VERSION "0.6.1"

NS_ :

BS_:

BU_: TestPC PVOptimizer HomeController Battery Inverter IPC
VAL_TABLE_ INV_State_Enum 3 "Fault" 2 "Grid_Forming" 1 "AC_Relays_Open" 0 "Unknown" ;
VAL_TABLE_ BB_State_Enum 4 "Fault" 3 "Block_Down" 2 "Active" 1 "Low_Voltage" 0 "Unknown" ;

BO_ 2150630656 BB_Control: 1 INV
 SG_ BB_StateReq : 0|8@1+ (1,0) [0|255] "" Vector__XXX

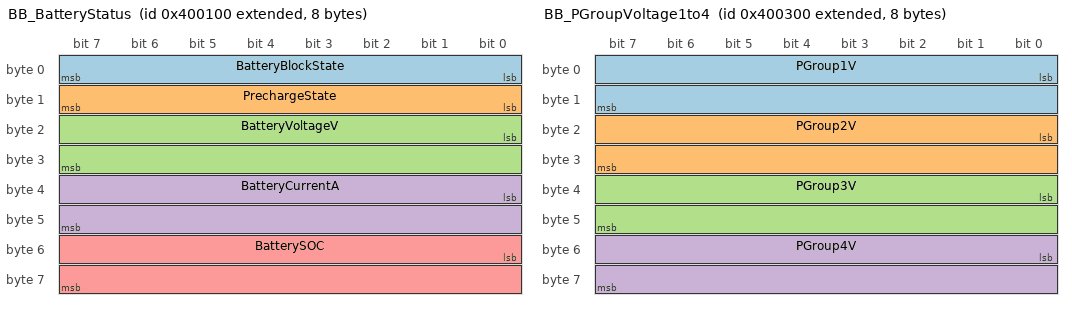
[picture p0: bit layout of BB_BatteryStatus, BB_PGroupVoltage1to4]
BO_ 2151678208 BB_BatteryStatus: 8 BB
 SG_ BatteryBlockState : 0|8@1+ (1,0) [0|255] "" Vector__XXX
 SG_ PrechargeState : 8|8@1+ (1,0) [0|255] "" Vector__XXX
 SG_ BatteryVoltageV : 16|16@1+ (0.001,0) [0|65.535] "V" Vector__XXX
 SG_ BatteryCurrentA : 32|16@1- (0.005,0) [-163.84|163.835] "A" Vector__XXX
 SG_ BatterySOC : 48|16@1+ (0.1,0) [0|100] "%" Vector__XXX

BO_ 2151678464 BB_DCDCStatus: 4 BB
 SG_ DCBusVoltageV : 0|16@1+ (0.01,0) [0|655.35] "V" Vector__XXX
 SG_ DCBusCurrentA : 16|16@1- (0.005,0) [-163.84|163.835] "A" Vector__XXX

BO_ 2151678720 BB_PGroupVoltage1to4: 8 BB
 SG_ PGroup1V : 0|16@1+ (0.0001,0) [0|6.5535000000000005] "V" Vector__XXX
 SG_ PGroup2V : 16|16@1+ (0.0001,0) [0|6.5535000000000005] "V" Vector__XXX
 SG_ PGroup3V : 32|16@1+ (0.0001,0) [0|6.5535000000000005] "V" Vector__XXX
 SG_ PGroup4V : 48|16@1+ (0.0001,0) [0|6.5535000000000005] "V" Vector__XXX

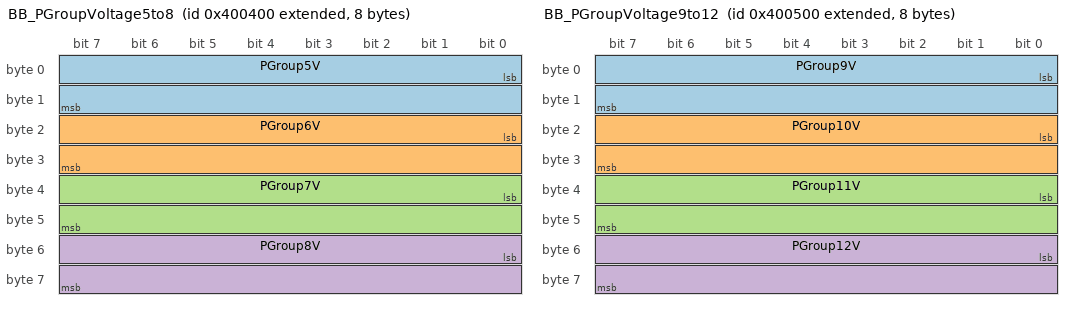
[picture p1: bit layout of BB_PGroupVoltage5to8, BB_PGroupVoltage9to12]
BO_ 2151678976 BB_PGroupVoltage5to8: 8 BB
 SG_ PGroup5V : 0|16@1+ (0.0001,0) [0|6.5535000000000005] "V" Vector__XXX
 SG_ PGroup6V : 16|16@1+ (0.0001,0) [0|6.5535000000000005] "V" Vector__XXX
 SG_ PGroup7V : 32|16@1+ (0.0001,0) [0|6.5535000000000005] "V" Vector__XXX
 SG_ PGroup8V : 48|16@1+ (0.0001,0) [0|6.5535000000000005] "V" Vector__XXX

BO_ 2151679232 BB_PGroupVoltage9to12: 8 BB
 SG_ PGroup9V : 0|16@1+ (0.0001,0) [0|6.5535000000000005] "V" Vector__XXX
 SG_ PGroup10V : 16|16@1+ (0.0001,0) [0|6.5535000000000005] "V" Vector__XXX
 SG_ PGroup11V : 32|16@1+ (0.0001,0) [0|6.5535000000000005] "V" Vector__XXX
 SG_ PGroup12V : 48|16@1+ (0.0001,0) [0|6.5535000000000005] "V" Vector__XXX

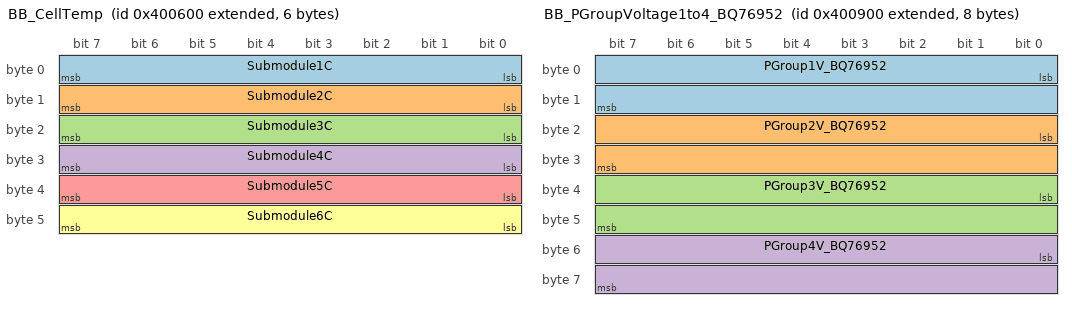
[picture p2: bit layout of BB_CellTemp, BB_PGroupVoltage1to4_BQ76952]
BO_ 2151679488 BB_CellTemp: 6 BB
 SG_ Submodule1C : 0|8@1+ (0.5,-40) [-40|87.5] "Celsius" Vector__XXX
 SG_ Submodule2C : 8|8@1+ (0.5,-40) [-40|87.5] "Celsius" Vector__XXX
 SG_ Submodule3C : 16|8@1+ (0.5,-40) [-40|87.5] "Celsius" Vector__XXX
 SG_ Submodule4C : 24|8@1+ (0.5,-40) [-40|87.5] "Celsius" Vector__XXX
 SG_ Submodule5C : 32|8@1+ (0.5,-40) [-40|87.5] "Celsius" Vector__XXX
 SG_ Submodule6C : 40|8@1+ (0.5,-40) [-40|87.5] "Celsius" Vector__XXX

BO_ 2151679744 BB_DCDCTemperatures: 3 BB
 SG_ BBHeatsinkC : 0|8@1+ (1,-60) [-60|195] "Celsius" Vector__XXX
 SG_ FanDutyCycle : 8|16@1+ (0.1,0) [0|100] "%" Vector__XXX

BO_ 2151680000 BB_CommandResetCMD: 1 BB
 SG_ BB_ResetReq : 0|8@1+ (1,0) [0|255] "" Vector__XXX

BO_ 2151680256 BB_PGroupVoltage1to4_BQ76952: 8 BB
 SG_ PGroup1V_BQ76952 : 0|16@1+ (0.0001,0) [0|6.5535000000000005] "V" Vector__XXX
 SG_ PGroup2V_BQ76952 : 16|16@1+ (0.0001,0) [0|6.5535000000000005] "V" Vector__XXX
 SG_ PGroup3V_BQ76952 : 32|16@1+ (0.0001,0) [0|6.5535000000000005] "V" Vector__XXX
 SG_ PGroup4V_BQ76952 : 48|16@1+ (0.0001,0) [0|6.5535000000000005] "V" Vector__XXX

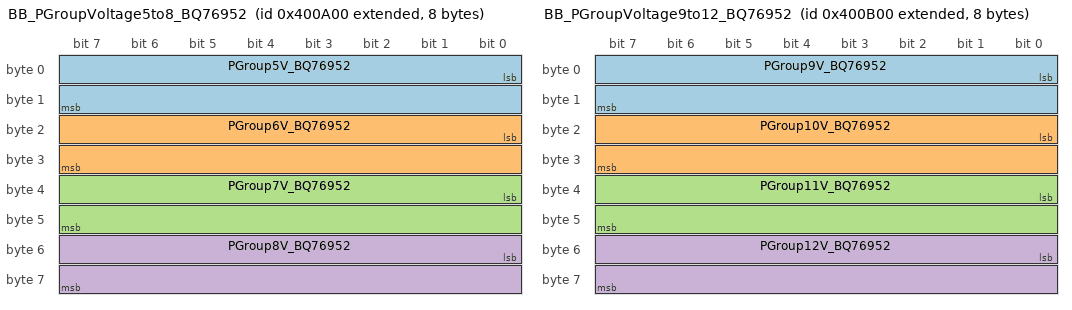
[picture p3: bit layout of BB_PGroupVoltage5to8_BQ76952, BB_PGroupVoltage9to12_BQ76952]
BO_ 2151680512 BB_PGroupVoltage5to8_BQ76952: 8 BB
 SG_ PGroup5V_BQ76952 : 0|16@1+ (0.0001,0) [0|6.5535000000000005] "V" Vector__XXX
 SG_ PGroup6V_BQ76952 : 16|16@1+ (0.0001,0) [0|6.5535000000000005] "V" Vector__XXX
 SG_ PGroup7V_BQ76952 : 32|16@1+ (0.0001,0) [0|6.5535000000000005] "V" Vector__XXX
 SG_ PGroup8V_BQ76952 : 48|16@1+ (0.0001,0) [0|6.5535000000000005] "V" Vector__XXX

BO_ 2151680768 BB_PGroupVoltage9to12_BQ76952: 8 BB
 SG_ PGroup9V_BQ76952 : 0|16@1+ (0.0001,0) [0|6.5535000000000005] "V" Vector__XXX
 SG_ PGroup10V_BQ76952 : 16|16@1+ (0.0001,0) [0|6.5535000000000005] "V" Vector__XXX
 SG_ PGroup11V_BQ76952 : 32|16@1+ (0.0001,0) [0|6.5535000000000005] "V" Vector__XXX
 SG_ PGroup12V_BQ76952 : 48|16@1+ (0.0001,0) [0|6.5535000000000005] "V" Vector__XXX

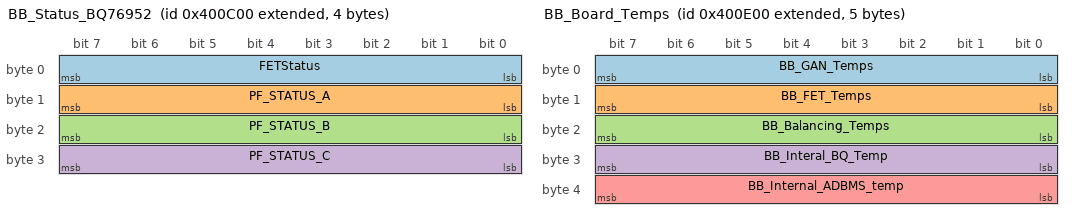
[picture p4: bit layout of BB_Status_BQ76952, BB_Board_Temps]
BO_ 2151681024 BB_Status_BQ76952: 4 BB
 SG_ FETStatus : 0|8@1+ (1,0) [0|255] "" Vector__XXX
 SG_ PF_STATUS_A : 8|8@1+ (1,0) [0|255] "" Vector__XXX
 SG_ PF_STATUS_B : 16|8@1+ (1,0) [0|255] "" Vector__XXX
 SG_ PF_STATUS_C : 24|8@1+ (1,0) [0|255] "" Vector__XXX

BO_ 2151681280 BB_Interrupt_Status: 5 BB
 SG_ BB_10Hz_Runtime : 0|32@1+ (1,0) [0|4294967295] "" Vector__XXX
 SG_ BB_Percent_Usage_10hz : 32|8@1+ (1,0) [0|255] "" Vector__XXX

BO_ 2151681536 BB_Board_Temps: 5 BB
 SG_ BB_GAN_Temps : 0|8@1+ (0.5,-40) [-40|87.5] "Celsius" Vector__XXX
 SG_ BB_FET_Temps : 8|8@1+ (0.5,-40) [-40|87.5] "Celsius" Vector__XXX
 SG_ BB_Balancing_Temps : 16|8@1+ (0.5,-40) [-40|87.5] "Celsius" Vector__XXX
 SG_ BB_Interal_BQ_Temp : 24|8@1+ (0.5,-40) [-40|87.5] "Celsius" Vector__XXX
 SG_ BB_Internal_ADBMS_temp : 32|8@1+ (0.5,-40) [-40|87.5] "Celsius" Vector__XXX

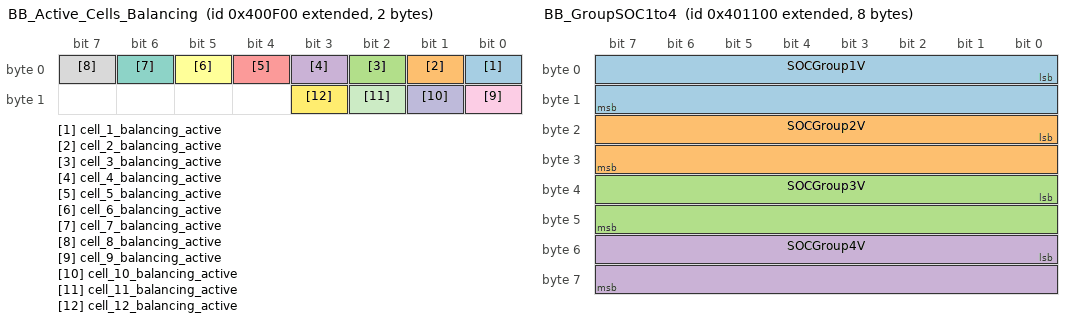
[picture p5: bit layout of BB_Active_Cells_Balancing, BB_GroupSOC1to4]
BO_ 2151681792 BB_Active_Cells_Balancing: 2 BB
 SG_ cell_1_balancing_active : 0|1@1+ (1,0) [0|1] "" Vector__XXX
 SG_ cell_2_balancing_active : 1|1@1+ (1,0) [0|1] "" Vector__XXX
 SG_ cell_3_balancing_active : 2|1@1+ (1,0) [0|1] "" Vector__XXX
 SG_ cell_4_balancing_active : 3|1@1+ (1,0) [0|1] "" Vector__XXX
 SG_ cell_5_balancing_active : 4|1@1+ (1,0) [0|1] "" Vector__XXX
 SG_ cell_6_balancing_active : 5|1@1+ (1,0) [0|1] "" Vector__XXX
 SG_ cell_7_balancing_active : 6|1@1+ (1,0) [0|1] "" Vector__XXX
 SG_ cell_8_balancing_active : 7|1@1+ (1,0) [0|1] "" Vector__XXX
 SG_ cell_9_balancing_active : 8|1@1+ (1,0) [0|1] "" Vector__XXX
 SG_ cell_10_balancing_active : 9|1@1+ (1,0) [0|1] "" Vector__XXX
 SG_ cell_11_balancing_active : 10|1@1+ (1,0) [0|1] "" Vector__XXX
 SG_ cell_12_balancing_active : 11|1@1+ (1,0) [0|1] "" Vector__XXX

BO_ 2151682304 BB_GroupSOC1to4: 8 BB
 SG_ SOCGroup1V : 0|16@1+ (0.1,0) [0|100] "%" Vector__XXX
 SG_ SOCGroup2V : 16|16@1+ (0.1,0) [0|100] "%" Vector__XXX
 SG_ SOCGroup3V : 32|16@1+ (0.1,0) [0|100] "%" Vector__XXX
 SG_ SOCGroup4V : 48|16@1+ (0.1,0) [0|100] "%" Vector__XXX

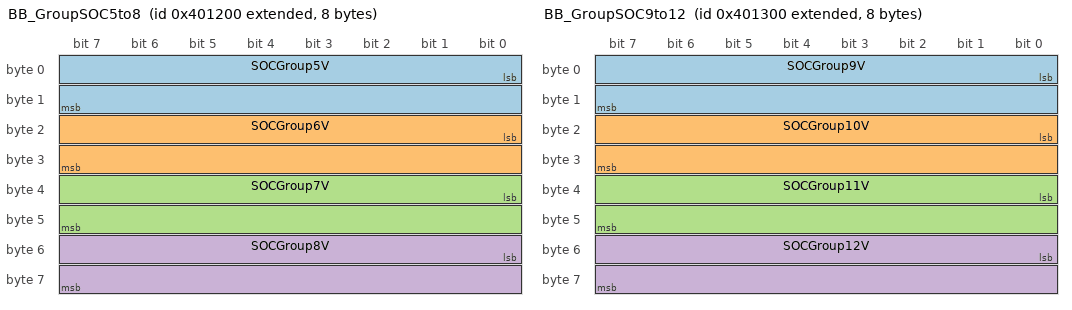
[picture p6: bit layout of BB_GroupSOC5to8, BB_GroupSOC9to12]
BO_ 2151682560 BB_GroupSOC5to8: 8 BB
 SG_ SOCGroup5V : 0|16@1+ (0.1,0) [0|100] "%" Vector__XXX
 SG_ SOCGroup6V : 16|16@1+ (0.1,0) [0|100] "%" Vector__XXX
 SG_ SOCGroup7V : 32|16@1+ (0.1,0) [0|100] "%" Vector__XXX
 SG_ SOCGroup8V : 48|16@1+ (0.1,0) [0|100] "%" Vector__XXX

BO_ 2151682816 BB_GroupSOC9to12: 8 BB
 SG_ SOCGroup9V : 0|16@1+ (0.1,0) [0|100] "%" Vector__XXX
 SG_ SOCGroup10V : 16|16@1+ (0.1,0) [0|100] "%" Vector__XXX
 SG_ SOCGroup11V : 32|16@1+ (0.1,0) [0|100] "%" Vector__XXX
 SG_ SOCGroup12V : 48|16@1+ (0.1,0) [0|100] "%" Vector__XXX

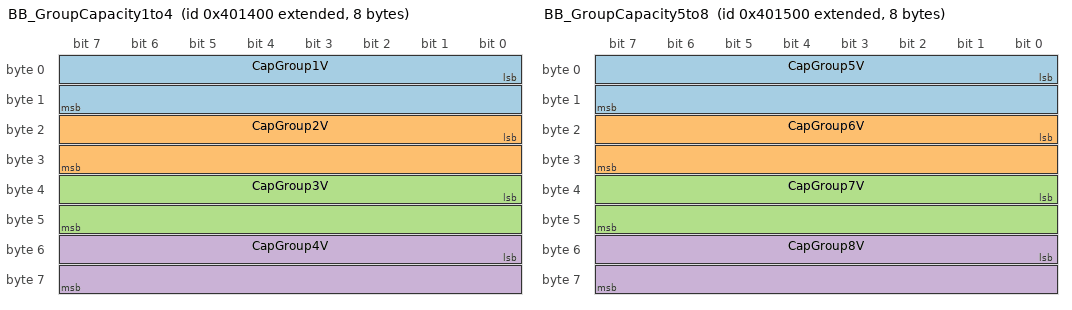
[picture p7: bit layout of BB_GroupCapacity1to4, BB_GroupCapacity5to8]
BO_ 2151683072 BB_GroupCapacity1to4: 8 BB
 SG_ CapGroup1V : 0|16@1+ (0.1,0) [0|100] "%" Vector__XXX
 SG_ CapGroup2V : 16|16@1+ (0.1,0) [0|100] "%" Vector__XXX
 SG_ CapGroup3V : 32|16@1+ (0.1,0) [0|100] "%" Vector__XXX
 SG_ CapGroup4V : 48|16@1+ (0.1,0) [0|100] "%" Vector__XXX

BO_ 2151683328 BB_GroupCapacity5to8: 8 BB
 SG_ CapGroup5V : 0|16@1+ (0.1,0) [0|100] "%" Vector__XXX
 SG_ CapGroup6V : 16|16@1+ (0.1,0) [0|100] "%" Vector__XXX
 SG_ CapGroup7V : 32|16@1+ (0.1,0) [0|100] "%" Vector__XXX
 SG_ CapGroup8V : 48|16@1+ (0.1,0) [0|100] "%" Vector__XXX

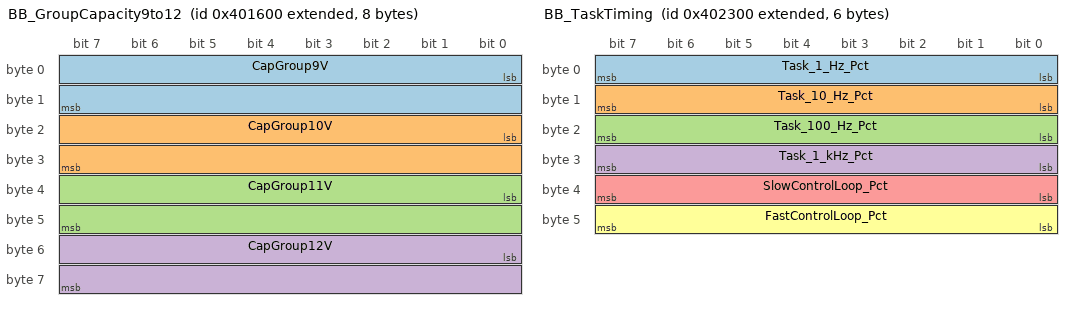
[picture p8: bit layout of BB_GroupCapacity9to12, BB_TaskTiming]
BO_ 2151683584 BB_GroupCapacity9to12: 8 BB
 SG_ CapGroup9V : 0|16@1+ (0.1,0) [0|100] "%" Vector__XXX
 SG_ CapGroup10V : 16|16@1+ (0.1,0) [0|100] "%" Vector__XXX
 SG_ CapGroup11V : 32|16@1+ (0.1,0) [0|100] "%" Vector__XXX
 SG_ CapGroup12V : 48|16@1+ (0.1,0) [0|100] "%" Vector__XXX

BO_ 2151683840 BB_Status_PF_Safety: 7 BB
 SG_ Reserved_0A : 0|1@1+ (1,0) [0|1] "" Vector__XXX
 SG_ Reserved_1A : 1|1@1+ (1,0) [0|1] "" Vector__XXX
 SG_ SafetyStatusA_CellUV_fault : 2|1@1+ (1,0) [0|1] "" Vector__XXX
 SG_ SafetyStatusA_CellOV_fault : 3|1@1+ (1,0) [0|1] "" Vector__XXX
 SG_ SatefyStatusA_OCCharge_fault : 4|1@1+ (1,0) [0|1] "" Vector__XXX
 SG_ SatefyStatusA_OCDischarge1_fault : 5|1@1+ (1,0) [0|1] "" Vector__XXX
 SG_ SatefyStatusA_OCDischarge2_fault : 6|1@1+ (1,0) [0|1] "" Vector__XXX
 SG_ SatefyStatusA_OCDischargeProt_fa : 7|1@1+ (1,0) [0|1] "" Vector__XXX
 SG_ SafetyStatusB_UTempCharge_fault : 8|1@1+ (1,0) [0|1] "" Vector__XXX
 SG_ SafetyStatusB_UTempDischarge_fau : 9|1@1+ (1,0) [0|1] "" Vector__XXX
 SG_ SafetyStatusB_IntUTemp_fault : 10|1@1+ (1,0) [0|1] "" Vector__XXX
 SG_ Reserved_11A : 11|1@1+ (1,0) [0|1] "" Vector__XXX
 SG_ SafetyStatusB_OTempCharge_fault : 12|1@1+ (1,0) [0|1] "" Vector__XXX
 SG_ SafetyStatusB_OTempDischarge_fau : 13|1@1+ (1,0) [0|1] "" Vector__XXX
 SG_ SafetyStatusB_IntOTemp_fault : 14|1@1+ (1,0) [0|1] "" Vector__XXX
 SG_ SatefyStatusB_FETOTemp_fault : 15|1@1+ (1,0) [0|1] "" Vector__XXX
 SG_ Reserved_16A : 16|1@1+ (1,0) [0|1] "" Vector__XXX
 SG_ SafetyStatusC_HostWDT_fault : 17|1@1+ (1,0) [0|1] "" Vector__XXX
 SG_ SafetyStatusC_PchgTimeout_fault : 18|1@1+ (1,0) [0|1] "" Vector__XXX
 SG_ Reserved_19A : 19|1@1+ (1,0) [0|1] "" Vector__XXX
 SG_ SafetyStatusC_COVLatch_fault : 20|1@1+ (1,0) [0|1] "" Vector__XXX
 SG_ SafetyStatusC_OCDischgLatch_faul : 21|1@1+ (1,0) [0|1] "" Vector__XXX
 SG_ SafetyStatusC_SCDischgLatch_faul : 22|1@1+ (1,0) [0|1] "" Vector__XXX
 SG_ SafetyStatusC_OCDischarge3_fault : 23|1@1+ (1,0) [0|1] "" Vector__XXX
 SG_ PFStatusA_CellUV_fault : 24|1@1+ (1,0) [0|1] "" Vector__XXX
 SG_ PFStatusA_CellOV_fault : 25|1@1+ (1,0) [0|1] "" Vector__XXX
 SG_ PFStatusA_OCCharge_fault : 26|1@1+ (1,0) [0|1] "" Vector__XXX
 SG_ PFStatusA_OCDischarge_fault : 27|1@1+ (1,0) [0|1] "" Vector__XXX
 SG_ PFStatusA_OT_fault : 28|1@1+ (1,0) [0|1] "" Vector__XXX
 SG_ Reserved_29A : 29|1@1+ (1,0) [0|1] "" Vector__XXX
 SG_ PFStatusA_CellOT_fault : 30|1@1+ (1,0) [0|1] "" Vector__XXX
 SG_ PFStatusA_CopperDepo_fault : 31|1@1+ (1,0) [0|1] "" Vector__XXX
 SG_ PFStatusB_ChgFet_fault : 32|1@1+ (1,0) [0|1] "" Vector__XXX
 SG_ PFStatusB_DChgFet_fault : 33|1@1+ (1,0) [0|1] "" Vector__XXX
 SG_ PFStatusB_2ndLvlProtFault : 34|1@1+ (1,0) [0|1] "" Vector__XXX
 SG_ PFStatusB_VImbalanceRest_fault : 35|1@1+ (1,0) [0|1] "" Vector__XXX
 SG_ PFStatusB_VImbalanceActive_fault : 36|1@1+ (1,0) [0|1] "" Vector__XXX
 SG_ Reserved_37A : 37|1@1+ (1,0) [0|1] "" Vector__XXX
 SG_ Reserved_38A : 38|1@1+ (1,0) [0|1] "" Vector__XXX
 SG_ PFStatusB_SCDischargeLatch_fault : 39|1@1+ (1,0) [0|1] "" Vector__XXX
 SG_ PFStatusC_OTPMem_fault : 40|1@1+ (1,0) [0|1] "" Vector__XXX
 SG_ PFStatusC_DataROM_fault : 41|1@1+ (1,0) [0|1] "" Vector__XXX
 SG_ PFStatusC_InstrROM_fault : 42|1@1+ (1,0) [0|1] "" Vector__XXX
 SG_ PFStatusC_IntLFO_fault : 43|1@1+ (1,0) [0|1] "" Vector__XXX
 SG_ PFStatusC_IntVRef_fault : 44|1@1+ (1,0) [0|1] "" Vector__XXX
 SG_ PFStatusC_IntVSS_fault : 45|1@1+ (1,0) [0|1] "" Vector__XXX
 SG_ PFStatusC_HrdwreMux_fault : 46|1@1+ (1,0) [0|1] "" Vector__XXX
 SG_ PFStatusC_Commanded_fault : 47|1@1+ (1,0) [0|1] "" Vector__XXX
 SG_ PFStatusD_StackVsSum_fault : 48|1@1+ (1,0) [0|1] "" Vector__XXX
 SG_ Reserved_49A : 49|1@1+ (1,0) [0|1] "" Vector__XXX
 SG_ Reserved_40A : 50|1@1+ (1,0) [0|1] "" Vector__XXX
 SG_ Reserved_51A : 51|1@1+ (1,0) [0|1] "" Vector__XXX
 SG_ Reserved_52A : 52|1@1+ (1,0) [0|1] "" Vector__XXX
 SG_ Reserved_53A : 53|1@1+ (1,0) [0|1] "" Vector__XXX
 SG_ Reserved_54A : 54|1@1+ (1,0) [0|1] "" Vector__XXX
 SG_ Reserved_55A : 55|1@1+ (1,0) [0|1] "" Vector__XXX

BO_ 2151684096 BB_Alert_PF_Safety: 7 BB
 SG_ Reserved_0B : 0|1@1+ (1,0) [0|1] "" Vector__XXX
 SG_ Reserved_1B : 1|1@1+ (1,0) [0|1] "" Vector__XXX
 SG_ SafetyAlertA_CellUV_alert : 2|1@1+ (1,0) [0|1] "" Vector__XXX
 SG_ SafetyAlertA_CellOV_alert : 3|1@1+ (1,0) [0|1] "" Vector__XXX
 SG_ SatefyAlertA_OCCharge_alert : 4|1@1+ (1,0) [0|1] "" Vector__XXX
 SG_ SatefyAlertA_OCDischarge1_alert : 5|1@1+ (1,0) [0|1] "" Vector__XXX
 SG_ SatefyAlertA_OCDischarge2_alert : 6|1@1+ (1,0) [0|1] "" Vector__XXX
 SG_ SatefyAlertA_OCDischargeProt_ale : 7|1@1+ (1,0) [0|1] "" Vector__XXX
 SG_ SafetyAlertB_UTempCharge_alert : 8|1@1+ (1,0) [0|1] "" Vector__XXX
 SG_ SafetyAlertB_UTempDischarge_aler : 9|1@1+ (1,0) [0|1] "" Vector__XXX
 SG_ SafetyAlertB_IntUTemp_alert : 10|1@1+ (1,0) [0|1] "" Vector__XXX
 SG_ Reserved_11B : 11|1@1+ (1,0) [0|1] "" Vector__XXX
 SG_ SafetyAlertB_OTempCharge_alert : 12|1@1+ (1,0) [0|1] "" Vector__XXX
 SG_ SafetyAlertB_OTempDischarge_aler : 13|1@1+ (1,0) [0|1] "" Vector__XXX
 SG_ SafetyAlertB_IntOTemp_alert : 14|1@1+ (1,0) [0|1] "" Vector__XXX
 SG_ SatefyAlertB_FETOTemp_alert : 15|1@1+ (1,0) [0|1] "" Vector__XXX
 SG_ Reserved_16B : 16|1@1+ (1,0) [0|1] "" Vector__XXX
 SG_ Reserved_17B : 17|1@1+ (1,0) [0|1] "" Vector__XXX
 SG_ Reserved_18B : 18|1@1+ (1,0) [0|1] "" Vector__XXX
 SG_ SafetyAlertC_PchgTimeout_alert : 19|1@1+ (1,0) [0|1] "" Vector__XXX
 SG_ SafetyAlertC_COVLatch_alert : 20|1@1+ (1,0) [0|1] "" Vector__XXX
 SG_ SafetyAlertC_OCDischgLatch_alert : 21|1@1+ (1,0) [0|1] "" Vector__XXX
 SG_ SafetyAlertC_SCDischgLatch_alert : 22|1@1+ (1,0) [0|1] "" Vector__XXX
 SG_ SafetyAlertC_OCDischarge3_alert : 23|1@1+ (1,0) [0|1] "" Vector__XXX
 SG_ PFAlertA_CellUV_alert : 24|1@1+ (1,0) [0|1] "" Vector__XXX
 SG_ PFAlertA_CellOV_alert : 25|1@1+ (1,0) [0|1] "" Vector__XXX
 SG_ PFAlertA_OCCharge_alert : 26|1@1+ (1,0) [0|1] "" Vector__XXX
 SG_ PFAlertA_OCDischarge_alert : 27|1@1+ (1,0) [0|1] "" Vector__XXX
 SG_ PFAlertA_OT_alert : 28|1@1+ (1,0) [0|1] "" Vector__XXX
 SG_ Reserved_29B : 29|1@1+ (1,0) [0|1] "" Vector__XXX
 SG_ PFAlertA_CellOT_alert : 30|1@1+ (1,0) [0|1] "" Vector__XXX
 SG_ PFAlertA_CopperDepo_alert : 31|1@1+ (1,0) [0|1] "" Vector__XXX
 SG_ PFAlertB_ChgFet_alert : 32|1@1+ (1,0) [0|1] "" Vector__XXX
 SG_ PFAlertB_DChgFet_alert : 33|1@1+ (1,0) [0|1] "" Vector__XXX
 SG_ PFAlertB_2ndLvlProt_alert : 34|1@1+ (1,0) [0|1] "" Vector__XXX
 SG_ PFAlertB_VImbalanceRest_alert : 35|1@1+ (1,0) [0|1] "" Vector__XXX
 SG_ PFAlertB_VImbalanceActive_alert : 36|1@1+ (1,0) [0|1] "" Vector__XXX
 SG_ Reserved_37B : 37|1@1+ (1,0) [0|1] "" Vector__XXX
 SG_ Reserved_38B : 38|1@1+ (1,0) [0|1] "" Vector__XXX
 SG_ PFAlertB_SCDischargeLatch_alert : 39|1@1+ (1,0) [0|1] "" Vector__XXX
 SG_ Reserved_40B : 40|1@1+ (1,0) [0|1] "" Vector__XXX
 SG_ Reserved_41B : 41|1@1+ (1,0) [0|1] "" Vector__XXX
 SG_ Reserved_42B : 42|1@1+ (1,0) [0|1] "" Vector__XXX
 SG_ PFAlertC_IntLFO_alert : 43|1@1+ (1,0) [0|1] "" Vector__XXX
 SG_ PFAlertC_IntVRef_alert : 44|1@1+ (1,0) [0|1] "" Vector__XXX
 SG_ PFAlertC_IntVSS_alert : 45|1@1+ (1,0) [0|1] "" Vector__XXX
 SG_ PFAlertC_HrdwreMux_alert : 46|1@1+ (1,0) [0|1] "" Vector__XXX
 SG_ Reserved_47B : 47|1@1+ (1,0) [0|1] "" Vector__XXX
 SG_ PFAlertD_StackVsSum_alert : 48|1@1+ (1,0) [0|1] "" Vector__XXX
 SG_ Reserved_49B : 49|1@1+ (1,0) [0|1] "" Vector__XXX
 SG_ Reserved_50B : 50|1@1+ (1,0) [0|1] "" Vector__XXX
 SG_ Reserved_51B : 51|1@1+ (1,0) [0|1] "" Vector__XXX
 SG_ Reserved_52B : 52|1@1+ (1,0) [0|1] "" Vector__XXX
 SG_ Reserved_53B : 53|1@1+ (1,0) [0|1] "" Vector__XXX
 SG_ Reserved_54B : 54|1@1+ (1,0) [0|1] "" Vector__XXX
 SG_ Reserved_55B : 55|1@1+ (1,0) [0|1] "" Vector__XXX

BO_ 2151684352 BB_FET_Battery_Status: 3 BB
 SG_ DevInConfigUpdateMode : 0|1@1+ (1,0) [0|1] "" Vector__XXX
 SG_ DevInPrechargeMode : 1|1@1+ (1,0) [0|1] "" Vector__XXX
 SG_ SleepIsAllowed : 2|1@1+ (1,0) [0|1] "" Vector__XXX
 SG_ ResetHasOccured : 3|1@1+ (1,0) [0|1] "" Vector__XXX
 SG_ ResetByWatchdog : 4|1@1+ (1,0) [0|1] "" Vector__XXX
 SG_ ActiveCOWCheck : 5|1@1+ (1,0) [0|1] "" Vector__XXX
 SG_ PendingOTPWrites : 6|1@1+ (1,0) [0|1] "" Vector__XXX
 SG_ OTPBlocked : 7|1@1+ (1,0) [0|1] "" Vector__XXX
 SG_ FullAccessMode : 8|1@1+ (1,0) [0|1] "" Vector__XXX
 SG_ SealedOrUnsealed : 9|1@1+ (1,0) [0|1] "" Vector__XXX
 SG_ FuseAsserted : 10|1@1+ (1,0) [0|1] "" Vector__XXX
 SG_ SafetyFaultTriggered : 11|1@1+ (1,0) [0|1] "" Vector__XXX
 SG_ PFFaultTriggered : 12|1@1+ (1,0) [0|1] "" Vector__XXX
 SG_ PendingShutdown : 13|1@1+ (1,0) [0|1] "" Vector__XXX
 SG_ Reserved_14C : 14|1@1+ (1,0) [0|1] "" Vector__XXX
 SG_ DeviceInSleepMode : 15|1@1+ (1,0) [0|1] "" Vector__XXX
 SG_ ChargeFEtEnabled : 16|1@1+ (1,0) [0|1] "" Vector__XXX
 SG_ PreChargeFETEnabled : 17|1@1+ (1,0) [0|1] "" Vector__XXX
 SG_ DischargeFETEnabled : 18|1@1+ (1,0) [0|1] "" Vector__XXX
 SG_ PredischargeFETEnabled : 19|1@1+ (1,0) [0|1] "" Vector__XXX
 SG_ DigitalChargeAsserted : 20|1@1+ (1,0) [0|1] "" Vector__XXX
 SG_ DigitalDischargeAsserted : 21|1@1+ (1,0) [0|1] "" Vector__XXX
 SG_ AlertPinAsserted : 22|1@1+ (1,0) [0|1] "" Vector__XXX
 SG_ Reserved_23C : 23|1@1+ (1,0) [0|1] "" Vector__XXX

BO_ 2151686144 BB_SourceAddrClaimCmd: 4 BB
 SG_ SerialNumber : 0|32@1+ (1,0) [0|4294967295] "" Vector__XXX

BO_ 2151686400 BB_RealTimeClock: 8 BB
 SG_ Time_ms : 0|64@1+ (1,0) [0|18446744073709551615] "milliseconds" Vector__XXX

BO_ 2151686656 BB_SetRealTimeClock: 8 HC
 SG_ Time_ms : 0|64@1+ (1,0) [0|18446744073709551615] "milliseconds" Vector__XXX

BO_ 2151686912 BB_TaskTiming: 6 BB
 SG_ Task_1_Hz_Pct : 0|8@1+ (1,0) [0|255] "pct" Vector__XXX
 SG_ Task_10_Hz_Pct : 8|8@1+ (1,0) [0|255] "pct" Vector__XXX
 SG_ Task_100_Hz_Pct : 16|8@1+ (1,0) [0|255] "pct" Vector__XXX
 SG_ Task_1_kHz_Pct : 24|8@1+ (1,0) [0|255] "pct" Vector__XXX
 SG_ SlowControlLoop_Pct : 32|8@1+ (1,0) [0|255] "pct" Vector__XXX
 SG_ FastControlLoop_Pct : 40|8@1+ (1,0) [0|255] "pct" Vector__XXX

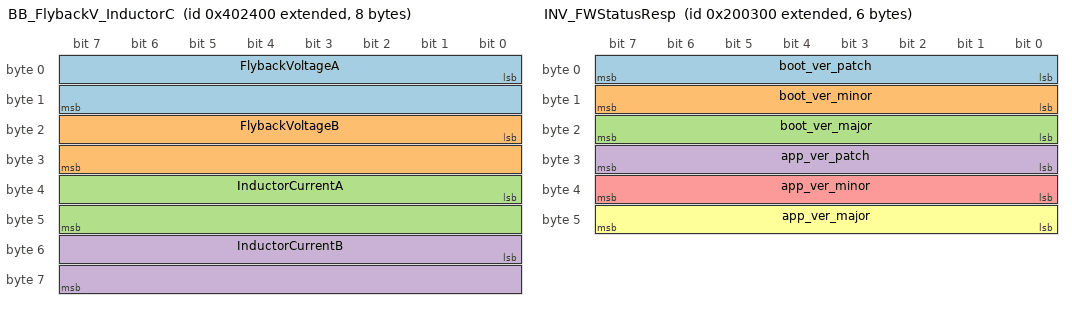
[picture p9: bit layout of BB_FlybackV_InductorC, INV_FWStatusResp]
BO_ 2151687168 BB_FlybackV_InductorC: 8 BB
 SG_ FlybackVoltageA : 0|16@1+ (0.01,0) [0|655.35] "V" Vector__XXX
 SG_ FlybackVoltageB : 16|16@1+ (0.01,0) [0|655.35] "V" Vector__XXX
 SG_ InductorCurrentA : 32|16@1- (0.005,0) [-163.84|163.835] "A" Vector__XXX
 SG_ InductorCurrentB : 48|16@1- (0.005,0) [-163.84|163.835] "A" Vector__XXX

BO_ 2151687424 BB_TargetBusCurrent: 2 INV
 SG_ TargetBusCurrent : 0|16@1- (0.005,0) [-163.84|163.835] "A" Vector__XXX

BO_ 2151682048 BB_AlertMatrix: 3 BB
 SG_ BB_F001_PrimaryCellUndervoltageA : 0|1@1+ (1,0) [0|1] "" Vector__XXX
 SG_ BB_F002_SecondaryCellUndervoltag : 1|1@1+ (1,0) [0|1] "" Vector__XXX
 SG_ BB_F003_CellOvervoltageAlert : 2|1@1+ (1,0) [0|1] "A" Vector__XXX
 SG_ BB_F004_CellImbalanceAlert : 3|1@1+ (1,0) [0|1] "" Vector__XXX
 SG_ BB_F005_CellMismatchMeasurementA : 4|1@1+ (1,0) [0|1] "" Vector__XXX
 SG_ BB_F005_CellOvertempAlert : 5|1@1+ (1,0) [0|1] "" Vector__XXX
 SG_ BB_F006_BatteryFETOvertempAlert : 6|1@1+ (1,0) [0|1] "" Vector__XXX
 SG_ BB_F007_CellOpenWireAlert : 7|1@1+ (1,0) [0|1] "" Vector__XXX
 SG_ BB_F008_HW_CellUndervoltageAlert : 8|1@1+ (1,0) [0|1] "" Vector__XXX
 SG_ BB_F009_HW_CellOverVoltageAlert_ : 9|1@1+ (1,0) [0|1] "" Vector__XXX
 SG_ BB_F010_OvercurrentChargeAlert : 10|1@1+ (1,0) [0|1] "" Vector__XXX
 SG_ BB_F011_OvercurrentDischargeAler : 11|1@1+ (1,0) [0|1] "" Vector__XXX
 SG_ BB_F012_OTPMemoryFailAlert : 12|1@1+ (1,0) [0|1] "" Vector__XXX
 SG_ BB_F013_DataROMFailAlert : 13|1@1+ (1,0) [0|1] "" Vector__XXX
 SG_ BB_F014_InstructionROMFailAlert : 14|1@1+ (1,0) [0|1] "" Vector__XXX
 SG_ BB_F015_LFOFailAlert : 15|1@1+ (1,0) [0|1] "" Vector__XXX
 SG_ BB_F016_VoltageRefFailAlert : 16|1@1+ (1,0) [0|1] "" Vector__XXX
 SG_ BB_F017_InternalVSSMEasurementFa : 17|1@1+ (1,0) [0|1] "" Vector__XXX
 SG_ BB_F018_ComparatorMuxFailAlert : 18|1@1+ (1,0) [0|1] "" Vector__XXX
 SG_ BB_F019_StackVsSumCellMismatchAl : 19|1@1+ (1,0) [0|1] "" Vector__XXX

BO_ 2149581056 INV_FWUpgradeTx: 8 HC

BO_ 2149581312 INV_FWUpgradeRx: 8 INV

BO_ 2149581568 INV_FWStatusResp: 6 INV
 SG_ boot_ver_patch : 0|8@1+ (1,0) [0|255] "" Vector__XXX
 SG_ boot_ver_minor : 8|8@1+ (1,0) [0|255] "" Vector__XXX
 SG_ boot_ver_major : 16|8@1+ (1,0) [0|255] "" Vector__XXX
 SG_ app_ver_patch : 24|8@1+ (1,0) [0|255] "" Vector__XXX
 SG_ app_ver_minor : 32|8@1+ (1,0) [0|255] "" Vector__XXX
 SG_ app_ver_major : 40|8@1+ (1,0) [0|255] "" Vector__XXX

BO_ 2149581824 BB_FWUpgradeTx: 8 HC

BO_ 2149582080 BB_FWUpgradeRx: 8 BB

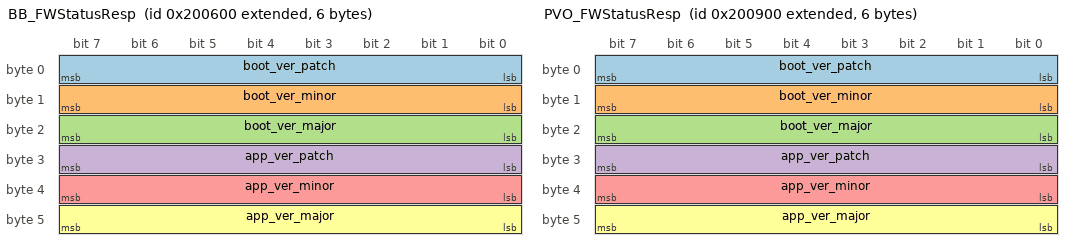
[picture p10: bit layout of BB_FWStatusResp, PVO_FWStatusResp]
BO_ 2149582336 BB_FWStatusResp: 6 BB
 SG_ boot_ver_patch : 0|8@1+ (1,0) [0|255] "" Vector__XXX
 SG_ boot_ver_minor : 8|8@1+ (1,0) [0|255] "" Vector__XXX
 SG_ boot_ver_major : 16|8@1+ (1,0) [0|255] "" Vector__XXX
 SG_ app_ver_patch : 24|8@1+ (1,0) [0|255] "" Vector__XXX
 SG_ app_ver_minor : 32|8@1+ (1,0) [0|255] "" Vector__XXX
 SG_ app_ver_major : 40|8@1+ (1,0) [0|255] "" Vector__XXX

BO_ 2149582592 PVO_FWUpgradeTx: 8 Vector__XXX

BO_ 2149582848 PVO_FWUpgradeRx: 8 Vector__XXX

BO_ 2149583104 PVO_FWStatusResp: 6 Vector__XXX
 SG_ boot_ver_patch : 0|8@1+ (1,0) [0|255] "" Vector__XXX
 SG_ boot_ver_minor : 8|8@1+ (1,0) [0|255] "" Vector__XXX
 SG_ boot_ver_major : 16|8@1+ (1,0) [0|255] "" Vector__XXX
 SG_ app_ver_patch : 24|8@1+ (1,0) [0|255] "" Vector__XXX
 SG_ app_ver_minor : 32|8@1+ (1,0) [0|255] "" Vector__XXX
 SG_ app_ver_major : 40|8@1+ (1,0) [0|255] "" Vector__XXX

BO_ 2149583360 DCM_FWUpgradeTx: 8 HC

BO_ 2149583616 DCM_FWUpgradeRx: 8 DCM

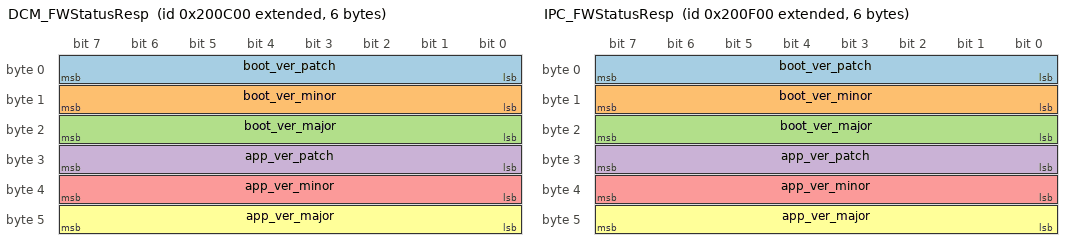
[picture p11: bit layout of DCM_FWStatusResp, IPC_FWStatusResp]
BO_ 2149583872 DCM_FWStatusResp: 6 DCM
 SG_ boot_ver_patch : 0|8@1+ (1,0) [0|255] "" Vector__XXX
 SG_ boot_ver_minor : 8|8@1+ (1,0) [0|255] "" Vector__XXX
 SG_ boot_ver_major : 16|8@1+ (1,0) [0|255] "" Vector__XXX
 SG_ app_ver_patch : 24|8@1+ (1,0) [0|255] "" Vector__XXX
 SG_ app_ver_minor : 32|8@1+ (1,0) [0|255] "" Vector__XXX
 SG_ app_ver_major : 40|8@1+ (1,0) [0|255] "" Vector__XXX

BO_ 2149584128 IPC_FWUpgradeTx: 8 HC

BO_ 2149584384 IPC_FWUpgradeRx: 8 IPC

BO_ 2149584640 IPC_FWStatusResp: 6 IPC
 SG_ boot_ver_patch : 0|8@1+ (1,0) [0|255] "" Vector__XXX
 SG_ boot_ver_minor : 8|8@1+ (1,0) [0|255] "" Vector__XXX
 SG_ boot_ver_major : 16|8@1+ (1,0) [0|255] "" Vector__XXX
 SG_ app_ver_patch : 24|8@1+ (1,0) [0|255] "" Vector__XXX
 SG_ app_ver_minor : 32|8@1+ (1,0) [0|255] "" Vector__XXX
 SG_ app_ver_major : 40|8@1+ (1,0) [0|255] "" Vector__XXX

BO_ 2149584896 GIP_FWUpgradeTx: 8 HC

BO_ 2149585152 GIP_FWUpgradeRx: 8 GIP

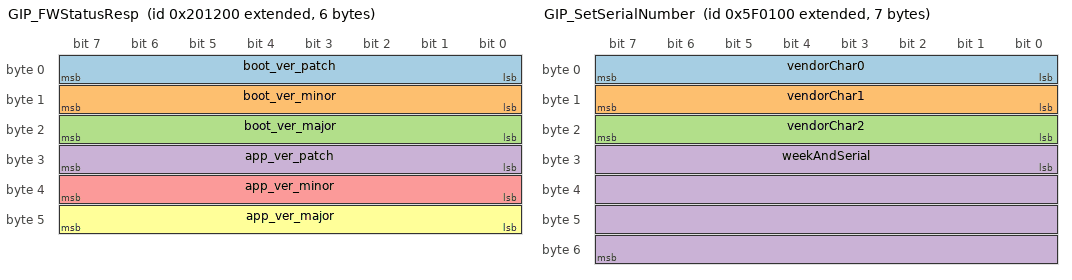
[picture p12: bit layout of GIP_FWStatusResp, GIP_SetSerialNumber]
BO_ 2149585408 GIP_FWStatusResp: 6 GIP
 SG_ boot_ver_patch : 0|8@1+ (1,0) [0|255] "" Vector__XXX
 SG_ boot_ver_minor : 8|8@1+ (1,0) [0|255] "" Vector__XXX
 SG_ boot_ver_major : 16|8@1+ (1,0) [0|255] "" Vector__XXX
 SG_ app_ver_patch : 24|8@1+ (1,0) [0|255] "" Vector__XXX
 SG_ app_ver_minor : 32|8@1+ (1,0) [0|255] "" Vector__XXX
 SG_ app_ver_major : 40|8@1+ (1,0) [0|255] "" Vector__XXX

BO_ 2153709568 GIP_TestMode: 1 GIP
 SG_ GIP_TestModeFlag : 0|8@1+ (1,0) [0|255] "" Vector__XXX

BO_ 2153709824 GIP_SetSerialNumber: 7 GIP
 SG_ vendorChar0 : 0|8@1+ (1,0) [0|255] "ascii" Vector__XXX
 SG_ vendorChar1 : 8|8@1+ (1,0) [0|255] "ascii" Vector__XXX
 SG_ vendorChar2 : 16|8@1+ (1,0) [0|255] "ascii" Vector__XXX
 SG_ weekAndSerial : 24|32@1+ (1,0) [0|4294967295] "" Vector__XXX

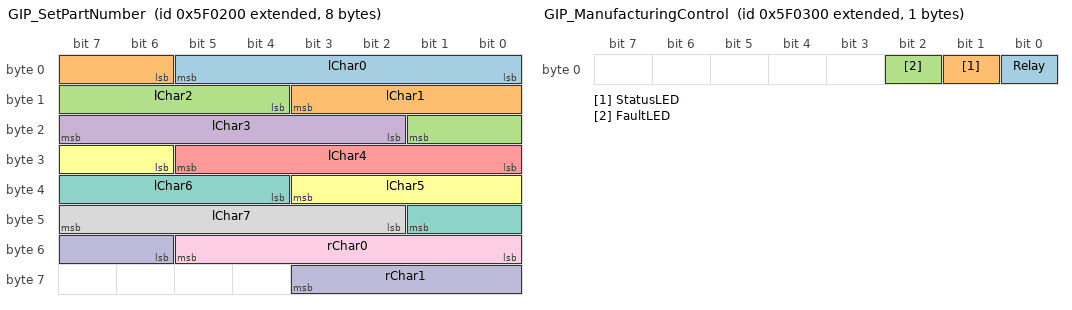
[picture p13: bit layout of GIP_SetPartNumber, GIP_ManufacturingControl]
BO_ 2153710080 GIP_SetPartNumber: 8 GIP
 SG_ lChar0 : 0|6@1+ (1,0) [0|63] "base64 alphabet" Vector__XXX
 SG_ lChar1 : 6|6@1+ (1,0) [0|63] "base64 alphabet" Vector__XXX
 SG_ lChar2 : 12|6@1+ (1,0) [0|63] "base64 alphabet" Vector__XXX
 SG_ lChar3 : 18|6@1+ (1,0) [0|63] "base64 alphabet" Vector__XXX
 SG_ lChar4 : 24|6@1+ (1,0) [0|63] "base64 alphabet" Vector__XXX
 SG_ lChar5 : 30|6@1+ (1,0) [0|63] "base64 alphabet" Vector__XXX
 SG_ lChar6 : 36|6@1+ (1,0) [0|63] "base64 alphabet" Vector__XXX
 SG_ lChar7 : 42|6@1+ (1,0) [0|63] "base64 alphabet" Vector__XXX
 SG_ rChar0 : 48|6@1+ (1,0) [0|63] "base64 alphabet" Vector__XXX
 SG_ rChar1 : 54|6@1+ (1,0) [0|63] "base64 alphabet" Vector__XXX

BO_ 2153710336 GIP_ManufacturingControl: 1 GIP
 SG_ Relay : 0|1@1+ (1,0) [0|1] "" Vector__XXX
 SG_ StatusLED : 1|1@1+ (1,0) [0|1] "" Vector__XXX
 SG_ FaultLED : 2|1@1+ (1,0) [0|1] "" Vector__XXX

BO_ 2153774592 GIP_SetTestedFlag: 1 GIP
 SG_ GIP_TestedFlag : 0|8@1+ (1,0) [0|255] "" Vector__XXX

BO_ 2152726784 GIP_Status: 2 GIP
 SG_ GIP_State : 0|8@1+ (1,0) [0|255] "" Vector__XXX
 SG_ GIP_Relay_State : 8|8@1+ (1,0) [0|255] "" Vector__XXX

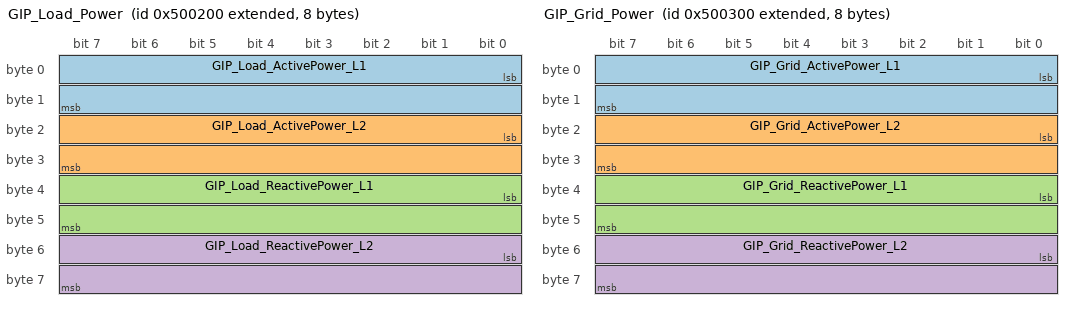
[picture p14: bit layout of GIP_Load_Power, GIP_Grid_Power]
BO_ 2152727040 GIP_Load_Power: 8 GIP
 SG_ GIP_Load_ActivePower_L1 : 0|16@1- (1,0) [-32768|32767] "W" Vector__XXX
 SG_ GIP_Load_ActivePower_L2 : 16|16@1- (1,0) [-32768|32767] "W" Vector__XXX
 SG_ GIP_Load_ReactivePower_L1 : 32|16@1- (1,0) [-32768|32767] "W" Vector__XXX
 SG_ GIP_Load_ReactivePower_L2 : 48|16@1- (1,0) [-32768|32767] "W" Vector__XXX

BO_ 2152727296 GIP_Grid_Power: 8 GIP
 SG_ GIP_Grid_ActivePower_L1 : 0|16@1- (1,0) [-32768|32767] "W" Vector__XXX
 SG_ GIP_Grid_ActivePower_L2 : 16|16@1- (1,0) [-32768|32767] "W" Vector__XXX
 SG_ GIP_Grid_ReactivePower_L1 : 32|16@1- (1,0) [-32768|32767] "W" Vector__XXX
 SG_ GIP_Grid_ReactivePower_L2 : 48|16@1- (1,0) [-32768|32767] "W" Vector__XXX

BO_ 2152727552 GIP_Load_ActiveEnergyImported: 8 GIP
 SG_ GIP_Load_ActiveEnergyImported_L1 : 0|32@1+ (1,0) [0|4294967295] "W-hr" Vector__XXX
 SG_ GIP_Load_ActiveEnergyImported_L2 : 32|32@1+ (1,0) [0|4294967295] "W-hr" Vector__XXX

BO_ 2152727808 GIP_Grid_ActiveEnergyImported: 8 GIP
 SG_ GIP_Grid_ActiveEnergyImported_L1 : 0|32@1+ (1,0) [0|4294967295] "W-hr" Vector__XXX
 SG_ GIP_Grid_ActiveEnergyImported_L2 : 32|32@1+ (1,0) [0|4294967295] "W-hr" Vector__XXX

BO_ 2152728064 GIP_Load_ActiveEnergyExported: 8 GIP
 SG_ GIP_Load_ActiveEnergyExported_L1 : 0|32@1+ (1,0) [0|4294967295] "W-hr" Vector__XXX
 SG_ GIP_Load_ActiveEnergyExported_L2 : 32|32@1+ (1,0) [0|4294967295] "W-hr" Vector__XXX

BO_ 2152728320 GIP_Grid_ActiveEnergyExported: 8 GIP
 SG_ GIP_Grid_ActiveEnergyExported_L1 : 0|32@1+ (1,0) [0|4294967295] "W-hr" Vector__XXX
 SG_ GIP_Grid_ActiveEnergyExported_L2 : 32|32@1+ (1,0) [0|4294967295] "W-hr" Vector__XXX

BO_ 2152728576 GIP_Load_TotalActiveEnergy: 8 GIP
 SG_ GIP_Load_TotalActiveEnergyImport : 0|32@1+ (1,0) [0|4294967295] "W-hr" Vector__XXX
 SG_ GIP_Load_TotalActiveEnergyExport : 32|32@1+ (1,0) [0|4294967295] "W-hr" Vector__XXX

BO_ 2152728832 GIP_Grid_TotalActiveEnergy: 8 GIP
 SG_ GIP_Grid_TotalActiveEnergyImport : 0|32@1+ (1,0) [0|4294967295] "W-hr" Vector__XXX
 SG_ GIP_Grid_TotalActiveEnergyExport : 32|32@1+ (1,0) [0|4294967295] "W-hr" Vector__XXX

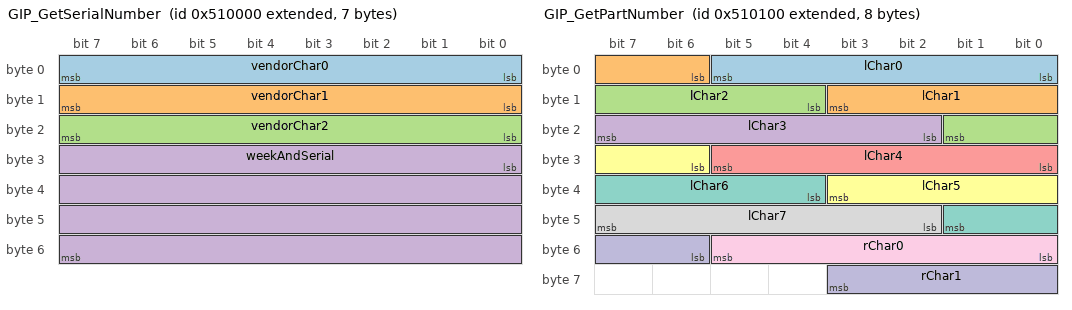
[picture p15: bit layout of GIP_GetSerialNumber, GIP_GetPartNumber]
BO_ 2152792064 GIP_GetSerialNumber: 7 GIP
 SG_ vendorChar0 : 0|8@1+ (1,0) [0|255] "ascii" Vector__XXX
 SG_ vendorChar1 : 8|8@1+ (1,0) [0|255] "ascii" Vector__XXX
 SG_ vendorChar2 : 16|8@1+ (1,0) [0|255] "ascii" Vector__XXX
 SG_ weekAndSerial : 24|32@1+ (1,0) [0|4294967295] "" Vector__XXX

BO_ 2152792320 GIP_GetPartNumber: 8 GIP
 SG_ lChar0 : 0|6@1+ (1,0) [0|63] "base64 alphabet" Vector__XXX
 SG_ lChar1 : 6|6@1+ (1,0) [0|63] "base64 alphabet" Vector__XXX
 SG_ lChar2 : 12|6@1+ (1,0) [0|63] "base64 alphabet" Vector__XXX
 SG_ lChar3 : 18|6@1+ (1,0) [0|63] "base64 alphabet" Vector__XXX
 SG_ lChar4 : 24|6@1+ (1,0) [0|63] "base64 alphabet" Vector__XXX
 SG_ lChar5 : 30|6@1+ (1,0) [0|63] "base64 alphabet" Vector__XXX
 SG_ lChar6 : 36|6@1+ (1,0) [0|63] "base64 alphabet" Vector__XXX
 SG_ lChar7 : 42|6@1+ (1,0) [0|63] "base64 alphabet" Vector__XXX
 SG_ rChar0 : 48|6@1+ (1,0) [0|63] "base64 alphabet" Vector__XXX
 SG_ rChar1 : 54|6@1+ (1,0) [0|63] "base64 alphabet" Vector__XXX

BO_ 2152792576 GIP_GetBootloaderVersion: 3 GIP
 SG_ Major : 0|8@1+ (1,0) [0|255] "" Vector__XXX
 SG_ Minor : 8|8@1+ (1,0) [0|255] "" Vector__XXX
 SG_ Patch : 16|8@1+ (1,0) [0|255] "" Vector__XXX

BO_ 2152792832 GIP_GetGitHash: 8 GIP
 SG_ GitHash : 0|64@1+ (1,0) [0|18446744073709551615] "" Vector__XXX

BO_ 2152857600 GIP_ResetCommand: 1 GIP
 SG_ Reset : 0|8@1+ (1,0) [0|255] "" Vector__XXX

BO_ 2148926464 INV_CommandStatusReqCMD: 2 HC
 SG_ INV_StateReq : 0|8@1+ (1,0) [0|255] "" Vector__XXX
 SG_ INV_L1L2InPhaseReq : 8|8@1+ (1,0) [0|255] "" Vector__XXX

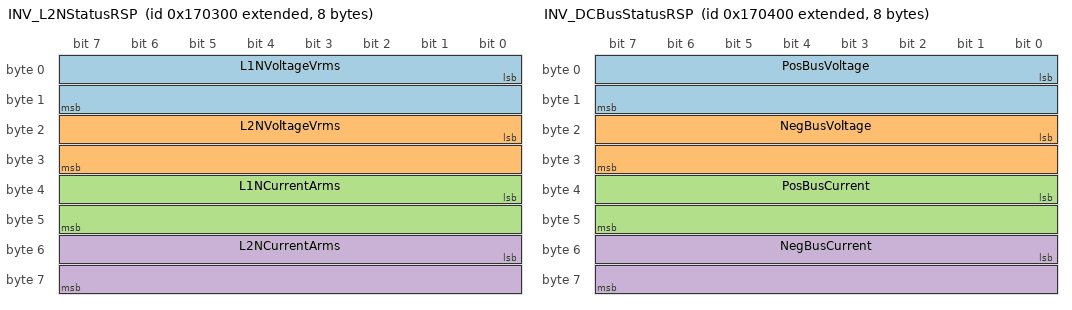
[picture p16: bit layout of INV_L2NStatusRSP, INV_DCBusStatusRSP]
BO_ 2148991744 INV_L2NStatusRSP: 8 INV
 SG_ L1NVoltageVrms : 0|16@1+ (0.01,0) [0|655.35] "V" Vector__XXX
 SG_ L2NVoltageVrms : 16|16@1+ (0.01,0) [0|655.35] "V" Vector__XXX
 SG_ L1NCurrentArms : 32|16@1- (0.005,0) [-163.84|163.835] "A" Vector__XXX
 SG_ L2NCurrentArms : 48|16@1- (0.005,0) [-163.84|163.835] "A" Vector__XXX

BO_ 2148991488 INV_L2LStatusRSP: 4 INV
 SG_ L1L2VoltageVrms : 0|16@1+ (0.01,0) [0|655.35] "V" Vector__XXX
 SG_ L1L2CurrentArms : 16|16@1- (0.005,0) [-163.84|163.835] "A" Vector__XXX

BO_ 2148992000 INV_DCBusStatusRSP: 8 INV
 SG_ PosBusVoltage : 0|16@1+ (0.01,0) [0|655.35] "V" Vector__XXX
 SG_ NegBusVoltage : 16|16@1+ (0.01,0) [0|655.35] "V" Vector__XXX
 SG_ PosBusCurrent : 32|16@1+ (0.005,0) [0|327.675] "A" Vector__XXX
 SG_ NegBusCurrent : 48|16@1+ (0.005,0) [0|327.675] "A" Vector__XXX

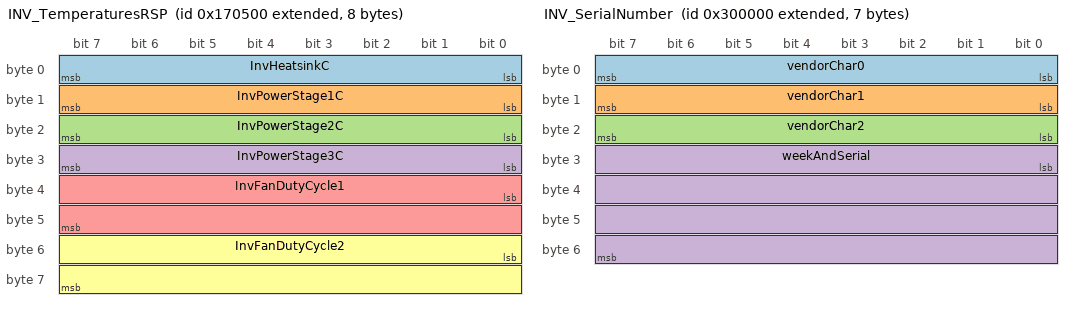
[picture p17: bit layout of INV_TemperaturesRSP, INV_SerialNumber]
BO_ 2148992256 INV_TemperaturesRSP: 8 INV
 SG_ InvHeatsinkC : 0|8@1+ (1,-60) [-60|195] "Celsius" Vector__XXX
 SG_ InvPowerStage1C : 8|8@1+ (1,-60) [-60|195] "Celsius" Vector__XXX
 SG_ InvPowerStage2C : 16|8@1+ (1,-60) [-60|195] "Celsius" Vector__XXX
 SG_ InvPowerStage3C : 24|8@1+ (1,-60) [-60|195] "Celsius" Vector__XXX
 SG_ InvFanDutyCycle1 : 32|16@1+ (0.1,0) [0|100] "%" Vector__XXX
 SG_ InvFanDutyCycle2 : 48|16@1+ (0.1,0) [0|100] "%" Vector__XXX

BO_ 2148991232 INV_StatusRSP: 3 INV
 SG_ InvState : 0|8@1+ (1,0) [0|255] "" Vector__XXX
 SG_ InvACRelay : 8|8@1+ (1,0) [0|255] "" Vector__XXX
 SG_ INV_L1L2InPhase : 16|8@1+ (1,0) [0|255] "" Vector__XXX

BO_ 2150236416 INV_ConnectCmd: 1 HC
 SG_ connected : 0|8@1+ (1,0) [0|255] "" Vector__XXX

BO_ 2149187840 INV_ConnectRsp: 1 INV
 SG_ connected : 0|8@1+ (1,0) [0|255] "" Vector__XXX

BO_ 2150236672 INV_PermitServiceCmd: 1 HC
 SG_ permitted : 0|8@1+ (1,0) [0|255] "" Vector__XXX

BO_ 2149188096 INV_PermitServiceRsp: 1 INV
 SG_ permitted : 0|8@1+ (1,0) [0|255] "" Vector__XXX

BO_ 2148925696 INV_CommandResetCMD: 1 INV
 SG_ INV_ResetReq : 0|8@1+ (1,0) [0|255] "" Vector__XXX

BO_ 2148929536 INV_Power: 4 INV
 SG_ activePower : 0|16@1- (1,0) [-32768|32767] "W" Vector__XXX
 SG_ reactivePower : 16|16@1- (1,0) [-32768|32767] "var" Vector__XXX

BO_ 2148929792 INV_Frequency: 2 INV
 SG_ frequency : 0|16@1+ (0.01,0) [0|655.35] "Hz" Vector__XXX

BO_ 2148930048 INV_AlarmState: 4 INV
 SG_ alarmState : 0|32@1+ (1,0) [0|4294967295] "" Vector__XXX

BO_ 2148930304 INV_RapidShutdown: 1 INV
 SG_ RapidShutdown : 0|8@1+ (1,0) [0|255] "" Vector__XXX

BO_ 2148536320 BB_SourceAddrClaimRsp: 5 HC
 SG_ SerialNumber : 0|32@1+ (1,0) [0|4294967295] "" Vector__XXX
 SG_ SlaveAddress : 32|8@1+ (1,0) [0|255] "" Vector__XXX

BO_ 2150629376 INV_SerialNumber: 7 INV
 SG_ vendorChar0 : 0|8@1+ (1,0) [0|255] "ascii" Vector__XXX
 SG_ vendorChar1 : 8|8@1+ (1,0) [0|255] "ascii" Vector__XXX
 SG_ vendorChar2 : 16|8@1+ (1,0) [0|255] "ascii" Vector__XXX
 SG_ weekAndSerial : 24|32@1+ (1,0) [0|4294967295] "" Vector__XXX

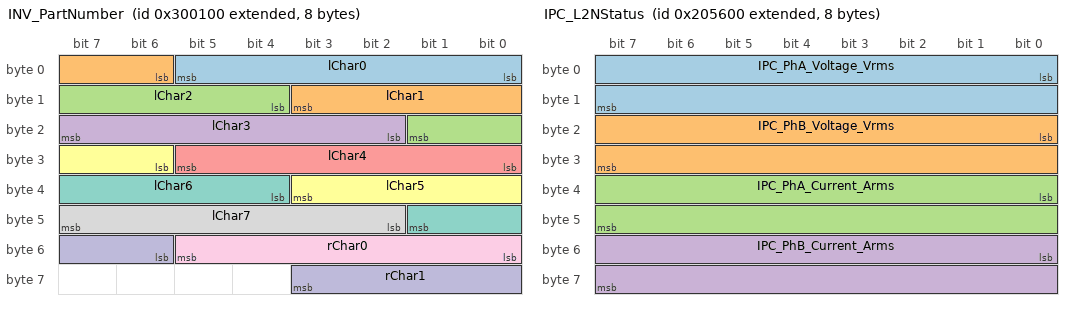
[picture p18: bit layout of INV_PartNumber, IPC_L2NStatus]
BO_ 2150629632 INV_PartNumber: 8 INV
 SG_ lChar0 : 0|6@1+ (1,0) [0|63] "base64 alphabet" Vector__XXX
 SG_ lChar1 : 6|6@1+ (1,0) [0|63] "base64 alphabet" Vector__XXX
 SG_ lChar2 : 12|6@1+ (1,0) [0|63] "base64 alphabet" Vector__XXX
 SG_ lChar3 : 18|6@1+ (1,0) [0|63] "base64 alphabet" Vector__XXX
 SG_ lChar4 : 24|6@1+ (1,0) [0|63] "base64 alphabet" Vector__XXX
 SG_ lChar5 : 30|6@1+ (1,0) [0|63] "base64 alphabet" Vector__XXX
 SG_ lChar6 : 36|6@1+ (1,0) [0|63] "base64 alphabet" Vector__XXX
 SG_ lChar7 : 42|6@1+ (1,0) [0|63] "base64 alphabet" Vector__XXX
 SG_ rChar0 : 48|6@1+ (1,0) [0|63] "base64 alphabet" Vector__XXX
 SG_ rChar1 : 54|6@1+ (1,0) [0|63] "base64 alphabet" Vector__XXX

BO_ 2149602560 IPC_Status: 2 IPC
 SG_ IPC_State : 0|8@1+ (1,0) [0|255] "" Vector__XXX
 SG_ IPC_Relay_Status : 8|8@1+ (1,0) [0|255] "" Vector__XXX

BO_ 2149602816 IPC_L2NStatus: 8 IPC
 SG_ IPC_PhA_Voltage_Vrms : 0|16@1+ (0.01,0) [0|655.35] "" Vector__XXX
 SG_ IPC_PhB_Voltage_Vrms : 16|16@1+ (0.01,0) [0|655.35] "" Vector__XXX
 SG_ IPC_PhA_Current_Arms : 32|16@1+ (0.01,0) [0|655.35] "" Vector__XXX
 SG_ IPC_PhB_Current_Arms : 48|16@1+ (0.01,0) [0|655.35] "" Vector__XXX

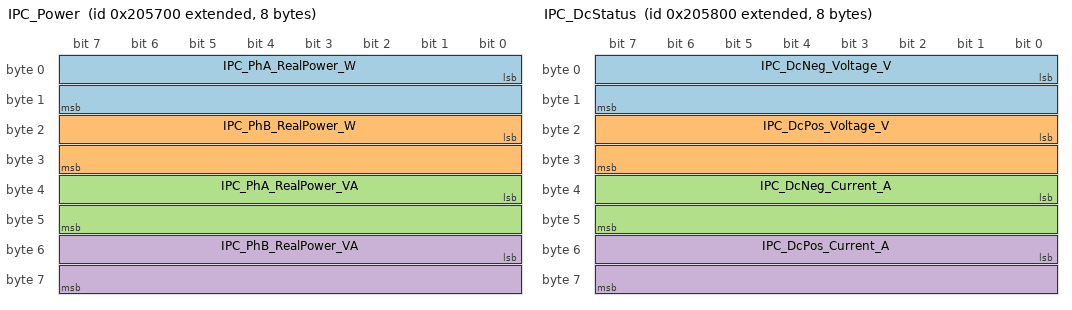
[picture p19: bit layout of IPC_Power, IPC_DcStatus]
BO_ 2149603072 IPC_Power: 8 IPC
 SG_ IPC_PhA_RealPower_W : 0|16@1+ (1,10000) [10000|75535] "" Vector__XXX
 SG_ IPC_PhB_RealPower_W : 16|16@1+ (1,10000) [10000|75535] "" Vector__XXX
 SG_ IPC_PhA_RealPower_VA : 32|16@1+ (1,0) [0|65535] "" Vector__XXX
 SG_ IPC_PhB_RealPower_VA : 48|16@1+ (1,0) [0|65535] "" Vector__XXX

BO_ 2149603328 IPC_DcStatus: 8 IPC
 SG_ IPC_DcNeg_Voltage_V : 0|16@1+ (0.0076,0) [0|498.066] "" Vector__XXX
 SG_ IPC_DcPos_Voltage_V : 16|16@1+ (0.0076,0) [0|498.066] "" Vector__XXX
 SG_ IPC_DcNeg_Current_A : 32|16@1+ (0.75,0) [0|49151.25] "" Vector__XXX
 SG_ IPC_DcPos_Current_A : 48|16@1+ (0.75,0) [0|49151.25] "" Vector__XXX

BO_ 2149603584 IPC_Temperatures: 2 IPC
 SG_ board_temp_C : 0|16@1+ (0.1,0) [0|6553.5] "" Vector__XXX

BO_ 2149603840 IPC_PowerTarget: 4 IPC
 SG_ IPC_RealPowerTarget_W : 0|16@1+ (1,10000) [10000|75535] "" Vector__XXX
 SG_ IPC_ReactivePowerTarget_VA : 16|16@1+ (1,10000) [10000|75535] "" Vector__XXX

BO_ 2149604096 IPC_Frequency: 2 IPC
 SG_ IPC_Frequency_Hz : 0|16@1+ (0.002,0) [0|131.07] "" Vector__XXX

BO_ 2149646336 IPC_ResetCommand: 0 IPC

BO_ 2148926976 PVO_CommandStatusReqCMD: 1 Vector__XXX
 SG_ PVO_StateReq : 0|8@1+ (1,0) [0|255] "" Vector__XXX

BO_ 2149122304 PVO_StatusRSP: 4 Vector__XXX
 SG_ PVOState : 0|8@1+ (1,0) [0|255] "" Vector__XXX
 SG_ PVO_3 : 8|8@1+ (1,0) [0|255] "" Vector__XXX
 SG_ PVO_2 : 16|8@1+ (1,0) [0|255] "" Vector__XXX
 SG_ PVO_1 : 24|8@1+ (1,0) [0|255] "" Vector__XXX

BO_ 2148926208 PVO_CommandResetCMD: 1 Vector__XXX
 SG_ PVO_ResetReq : 0|8@1+ (1,0) [0|255] "" Vector__XXX

BO_ 2150178816 INV_VoltVar_CurveStatus_CMD: 2 HC
 SG_ CurveEnabled : 0|8@1+ (1,0) [0|255] "" Vector__XXX
 SG_ CurveUpdateStatus : 8|8@1+ (1,0) [0|255] "" Vector__XXX

BO_ 2150179072 INV_VoltVar_Metadata_CMD: 2 HC
 SG_ CurveNumPoints : 0|8@1+ (1,0) [0|10] "" Vector__XXX
 SG_ yRefType : 8|8@1+ (1,0) [0|255] "" Vector__XXX

BO_ 2150179328 INV_VoltVar_Timings_CMD: 8 HC
 SG_ OpenLoopTms : 0|16@1+ (0.01,0) [0|655.35] "%capability/s" Vector__XXX
 SG_ RampDecTms : 16|16@1+ (0.01,0) [0|655.35] "%capability/s" Vector__XXX
 SG_ RampIncTms : 32|16@1+ (0.01,0) [0|655.35] "%capability/s" Vector__XXX
 SG_ RampPT1 : 48|16@1+ (0.01,0) [0|655.35] "s" Vector__XXX

BO_ 2150179584 INV_VoltVar_VRef_CMD: 7 HC
 SG_ enabled : 0|8@1+ (1,0) [0|255] "" Vector__XXX
 SG_ time_constant : 8|32@1+ (0.01,0) [0|42949672.95] "s" Vector__XXX
 SG_ v_ref : 40|16@1+ (0.01,0) [0|655.35] "%nominal" Vector__XXX

BO_ 2150179840 INV_VoltVar_Points_0_1_CMD: 8 HC
 SG_ x_0 : 0|16@1+ (0.01,0) [0|135.0] "%VRef" Vector__XXX
 SG_ y_0 : 16|16@1- (0.01,0) [-100.0|100.0] "%var capability" Vector__XXX
 SG_ x_1 : 32|16@1+ (0.01,0) [0|135.0] "%VRef" Vector__XXX
 SG_ y_1 : 48|16@1- (0.01,0) [-100.0|100.0] "%var capability" Vector__XXX

BO_ 2150180096 INV_VoltVar_Points_2_3_CMD: 8 HC
 SG_ x_2 : 0|16@1+ (0.01,0) [0|135.0] "%VRef" Vector__XXX
 SG_ y_2 : 16|16@1- (0.01,0) [-100.0|100.0] "%var capability" Vector__XXX
 SG_ x_3 : 32|16@1+ (0.01,0) [0|135.0] "%VRef" Vector__XXX
 SG_ y_3 : 48|16@1- (0.01,0) [-100.0|100.0] "%var capability" Vector__XXX

BO_ 2150180352 INV_VoltVar_Points_4_5_CMD: 8 HC
 SG_ x_4 : 0|16@1+ (0.01,0) [0|135.0] "%VRef" Vector__XXX
 SG_ y_4 : 16|16@1- (0.01,0) [-100.0|100.0] "%var capability" Vector__XXX
 SG_ x_5 : 32|16@1+ (0.01,0) [0|135.0] "%VRef" Vector__XXX
 SG_ y_5 : 48|16@1- (0.01,0) [-100.0|100.0] "%var capability" Vector__XXX

BO_ 2150180608 INV_VoltVar_Points_6_7_CMD: 8 HC
 SG_ x_6 : 0|16@1+ (0.01,0) [0|135.0] "%VRef" Vector__XXX
 SG_ y_6 : 16|16@1- (0.01,0) [-100.0|100.0] "%var capability" Vector__XXX
 SG_ x_7 : 32|16@1+ (0.01,0) [0|135.0] "%VRef" Vector__XXX
 SG_ y_7 : 48|16@1- (0.01,0) [-100.0|100.0] "%var capability" Vector__XXX

BO_ 2150180864 INV_VoltVar_Points_8_9_CMD: 8 HC
 SG_ x_8 : 0|16@1+ (0.01,0) [0|135.0] "%VRef" Vector__XXX
 SG_ y_8 : 16|16@1- (0.01,0) [-100.0|100.0] "%var capability" Vector__XXX
 SG_ x_9 : 32|16@1+ (0.01,0) [0|135.0] "%VRef" Vector__XXX
 SG_ y_9 : 48|16@1- (0.01,0) [-100.0|100.0] "%var capability" Vector__XXX

BO_ 2149130240 INV_VoltVar_CurveStatus_RSP: 2 INV
 SG_ CurveEnabled : 0|8@1+ (1,0) [0|255] "" Vector__XXX
 SG_ CurveUpdateStatus : 8|8@1+ (1,0) [0|255] "" Vector__XXX

BO_ 2149130496 INV_VoltVar_Metadata_RSP: 2 INV
 SG_ CurveNumPoints : 0|8@1+ (1,0) [0|10] "" Vector__XXX
 SG_ yRefType : 8|8@1+ (1,0) [0|255] "" Vector__XXX

BO_ 2149130752 INV_VoltVar_Timings_RSP: 8 INV
 SG_ OpenLoopTms : 0|16@1+ (0.01,0) [0|655.35] "%capability/s" Vector__XXX
 SG_ RampDecTms : 16|16@1+ (0.01,0) [0|655.35] "%capability/s" Vector__XXX
 SG_ RampIncTms : 32|16@1+ (0.01,0) [0|655.35] "%capability/s" Vector__XXX
 SG_ RampPT1 : 48|16@1+ (0.01,0) [0|655.35] "s" Vector__XXX

BO_ 2149131008 INV_VoltVar_VRef_RSP: 7 INV
 SG_ enabled : 0|8@1+ (1,0) [0|255] "" Vector__XXX
 SG_ time_constant : 8|32@1+ (0.01,0) [0|42949672.95] "s" Vector__XXX
 SG_ v_ref : 40|16@1+ (0.01,0) [0|655.35] "%nominal" Vector__XXX

BO_ 2149131264 INV_VoltVar_Points_0_1_RSP: 8 INV
 SG_ x_0 : 0|16@1+ (0.01,0) [0|135.0] "%VRef" Vector__XXX
 SG_ y_0 : 16|16@1- (0.01,0) [-100.0|100.0] "%var capability" Vector__XXX
 SG_ x_1 : 32|16@1+ (0.01,0) [0|135.0] "%VRef" Vector__XXX
 SG_ y_1 : 48|16@1- (0.01,0) [-100.0|100.0] "%var capability" Vector__XXX

BO_ 2149131520 INV_VoltVar_Points_2_3_RSP: 8 INV
 SG_ x_2 : 0|16@1+ (0.01,0) [0|135.0] "%VRef" Vector__XXX
 SG_ y_2 : 16|16@1- (0.01,0) [-100.0|100.0] "%var capability" Vector__XXX
 SG_ x_3 : 32|16@1+ (0.01,0) [0|135.0] "%VRef" Vector__XXX
 SG_ y_3 : 48|16@1- (0.01,0) [-100.0|100.0] "%var capability" Vector__XXX

BO_ 2149131776 INV_VoltVar_Points_4_5_RSP: 8 INV
 SG_ x_4 : 0|16@1+ (0.01,0) [0|135.0] "%VRef" Vector__XXX
 SG_ y_4 : 16|16@1- (0.01,0) [-100.0|100.0] "%var capability" Vector__XXX
 SG_ x_5 : 32|16@1+ (0.01,0) [0|135.0] "%VRef" Vector__XXX
 SG_ y_5 : 48|16@1- (0.01,0) [-100.0|100.0] "%var capability" Vector__XXX

BO_ 2149132032 INV_VoltVar_Points_6_7_RSP: 8 INV
 SG_ x_6 : 0|16@1+ (0.01,0) [0|135.0] "%VRef" Vector__XXX
 SG_ y_6 : 16|16@1- (0.01,0) [-100.0|100.0] "%var capability" Vector__XXX
 SG_ x_7 : 32|16@1+ (0.01,0) [0|135.0] "%VRef" Vector__XXX
 SG_ y_7 : 48|16@1- (0.01,0) [-100.0|100.0] "%var capability" Vector__XXX

BO_ 2149132288 INV_VoltVar_Points_8_9_RSP: 8 INV
 SG_ x_8 : 0|16@1+ (0.01,0) [0|135.0] "%VRef" Vector__XXX
 SG_ y_8 : 16|16@1- (0.01,0) [-100.0|100.0] "%var capability" Vector__XXX
 SG_ x_9 : 32|16@1+ (0.01,0) [0|135.0] "%VRef" Vector__XXX
 SG_ y_9 : 48|16@1- (0.01,0) [-100.0|100.0] "%var capability" Vector__XXX

BO_ 2150182912 INV_FreqWatt_CurveStatus_CMD: 2 HC
 SG_ CurveEnabled : 0|8@1+ (1,0) [0|255] "" Vector__XXX
 SG_ CurveUpdateStatus : 8|8@1+ (1,0) [0|255] "" Vector__XXX

BO_ 2150183168 INV_FreqWatt_Metadata_CMD: 1 HC
 SG_ CurveNumPoints : 0|8@1+ (1,0) [0|10] "" Vector__XXX

BO_ 2150183424 INV_FreqWatt_Timings_CMD: 8 HC
 SG_ OpenLoopTms : 0|16@1+ (0.01,0) [0|655.35] "%capability/s" Vector__XXX
 SG_ RampDecTms : 16|16@1+ (0.01,0) [0|655.35] "%capability/s" Vector__XXX
 SG_ RampIncTms : 32|16@1+ (0.01,0) [0|655.35] "%capability/s" Vector__XXX
 SG_ RampPT1 : 48|16@1+ (0.01,0) [0|655.35] "s" Vector__XXX

BO_ 2150183936 INV_FreqWatt_Points_0_1_CMD: 8 HC
 SG_ x_0 : 0|16@1+ (0.01,0) [0|655.35] "Hz" Vector__XXX
 SG_ y_0 : 16|16@1- (0.01,0) [-100.0|100.0] "%W capability" Vector__XXX
 SG_ x_1 : 32|16@1+ (0.01,0) [0|655.35] "Hz" Vector__XXX
 SG_ y_1 : 48|16@1- (0.01,0) [-100.0|100.0] "%W capability" Vector__XXX

BO_ 2150184192 INV_FreqWatt_Points_2_3_CMD: 8 HC
 SG_ x_2 : 0|16@1+ (0.01,0) [0|655.35] "Hz" Vector__XXX
 SG_ y_2 : 16|16@1- (0.01,0) [-100.0|100.0] "%W capability" Vector__XXX
 SG_ x_3 : 32|16@1+ (0.01,0) [0|655.35] "Hz" Vector__XXX
 SG_ y_3 : 48|16@1- (0.01,0) [-100.0|100.0] "%W capability" Vector__XXX

BO_ 2150184448 INV_FreqWatt_Points_4_5_CMD: 8 HC
 SG_ x_4 : 0|16@1+ (0.01,0) [0|655.35] "Hz" Vector__XXX
 SG_ y_4 : 16|16@1- (0.01,0) [-100.0|100.0] "%W capability" Vector__XXX
 SG_ x_5 : 32|16@1+ (0.01,0) [0|655.35] "Hz" Vector__XXX
 SG_ y_5 : 48|16@1- (0.01,0) [-100.0|100.0] "%W capability" Vector__XXX

BO_ 2150184704 INV_FreqWatt_Points_6_7_CMD: 8 HC
 SG_ x_6 : 0|16@1+ (0.01,0) [0|655.35] "Hz" Vector__XXX
 SG_ y_6 : 16|16@1- (0.01,0) [-100.0|100.0] "%W capability" Vector__XXX
 SG_ x_7 : 32|16@1+ (0.01,0) [0|655.35] "Hz" Vector__XXX
 SG_ y_7 : 48|16@1- (0.01,0) [-100.0|100.0] "%W capability" Vector__XXX

BO_ 2150184960 INV_FreqWatt_Points_8_9_CMD: 8 HC
 SG_ x_8 : 0|16@1+ (0.01,0) [0|655.35] "Hz" Vector__XXX
 SG_ y_8 : 16|16@1- (0.01,0) [-100.0|100.0] "%W capability" Vector__XXX
 SG_ x_9 : 32|16@1+ (0.01,0) [0|655.35] "Hz" Vector__XXX
 SG_ y_9 : 48|16@1- (0.01,0) [-100.0|100.0] "%W capability" Vector__XXX

BO_ 2149134336 INV_FreqWatt_CurveStatus_RSP: 2 INV
 SG_ CurveEnabled : 0|8@1+ (1,0) [0|255] "" Vector__XXX
 SG_ CurveUpdateStatus : 8|8@1+ (1,0) [0|255] "" Vector__XXX

BO_ 2149134592 INV_FreqWatt_Metadata_RSP: 1 INV
 SG_ CurveNumPoints : 0|8@1+ (1,0) [0|10] "" Vector__XXX

BO_ 2149134848 INV_FreqWatt_Timings_RSP: 8 INV
 SG_ OpenLoopTms : 0|16@1+ (0.01,0) [0|655.35] "%capability/s" Vector__XXX
 SG_ RampDecTms : 16|16@1+ (0.01,0) [0|655.35] "%capability/s" Vector__XXX
 SG_ RampIncTms : 32|16@1+ (0.01,0) [0|655.35] "%capability/s" Vector__XXX
 SG_ RampPT1 : 48|16@1+ (0.01,0) [0|655.35] "s" Vector__XXX

BO_ 2149135360 INV_FreqWatt_Points_0_1_RSP: 8 INV
 SG_ x_0 : 0|16@1+ (0.01,0) [0|655.35] "Hz" Vector__XXX
 SG_ y_0 : 16|16@1- (0.01,0) [-100.0|100.0] "%W capability" Vector__XXX
 SG_ x_1 : 32|16@1+ (0.01,0) [0|655.35] "Hz" Vector__XXX
 SG_ y_1 : 48|16@1- (0.01,0) [-100.0|100.0] "%W capability" Vector__XXX

BO_ 2149135616 INV_FreqWatt_Points_2_3_RSP: 8 INV
 SG_ x_2 : 0|16@1+ (0.01,0) [0|655.35] "Hz" Vector__XXX
 SG_ y_2 : 16|16@1- (0.01,0) [-100.0|100.0] "%W capability" Vector__XXX
 SG_ x_3 : 32|16@1+ (0.01,0) [0|655.35] "Hz" Vector__XXX
 SG_ y_3 : 48|16@1- (0.01,0) [-100.0|100.0] "%W capability" Vector__XXX

BO_ 2149135872 INV_FreqWatt_Points_4_5_RSP: 8 INV
 SG_ x_4 : 0|16@1+ (0.01,0) [0|655.35] "Hz" Vector__XXX
 SG_ y_4 : 16|16@1- (0.01,0) [-100.0|100.0] "%W capability" Vector__XXX
 SG_ x_5 : 32|16@1+ (0.01,0) [0|655.35] "Hz" Vector__XXX
 SG_ y_5 : 48|16@1- (0.01,0) [-100.0|100.0] "%W capability" Vector__XXX

BO_ 2149136128 INV_FreqWatt_Points_6_7_RSP: 8 INV
 SG_ x_6 : 0|16@1+ (0.01,0) [0|655.35] "Hz" Vector__XXX
 SG_ y_6 : 16|16@1- (0.01,0) [-100.0|100.0] "%W capability" Vector__XXX
 SG_ x_7 : 32|16@1+ (0.01,0) [0|655.35] "Hz" Vector__XXX
 SG_ y_7 : 48|16@1- (0.01,0) [-100.0|100.0] "%W capability" Vector__XXX

BO_ 2149136384 INV_FreqWatt_Points_8_9_RSP: 8 INV
 SG_ x_8 : 0|16@1+ (0.01,0) [0|655.35] "Hz" Vector__XXX
 SG_ y_8 : 16|16@1- (0.01,0) [-100.0|100.0] "%W capability" Vector__XXX
 SG_ x_9 : 32|16@1+ (0.01,0) [0|655.35] "Hz" Vector__XXX
 SG_ y_9 : 48|16@1- (0.01,0) [-100.0|100.0] "%W capability" Vector__XXX

BO_ 2150187008 INV_VoltWatt_CurveStatus_CMD: 2 HC
 SG_ CurveEnabled : 0|8@1+ (1,0) [0|255] "" Vector__XXX
 SG_ CurveUpdateStatus : 8|8@1+ (1,0) [0|255] "" Vector__XXX

BO_ 2150187264 INV_VoltWatt_Metadata_CMD: 2 HC
 SG_ CurveNumPoints : 0|8@1+ (1,0) [0|10] "" Vector__XXX
 SG_ yRefType : 8|8@1+ (1,0) [0|255] "" Vector__XXX

BO_ 2150187520 INV_VoltWatt_Timings_CMD: 8 HC
 SG_ OpenLoopTms : 0|16@1+ (0.01,0) [0|655.35] "%capability/s" Vector__XXX
 SG_ RampDecTms : 16|16@1+ (0.01,0) [0|655.35] "%capability/s" Vector__XXX
 SG_ RampIncTms : 32|16@1+ (0.01,0) [0|655.35] "%capability/s" Vector__XXX
 SG_ RampPT1 : 48|16@1+ (0.01,0) [0|655.35] "s" Vector__XXX

BO_ 2150188032 INV_VoltWatt_Points_0_1_CMD: 8 HC
 SG_ x_0 : 0|16@1+ (0.01,0) [0|135.0] "%VRef" Vector__XXX
 SG_ y_0 : 16|16@1- (0.01,0) [-100.0|100.0] "%W capability" Vector__XXX
 SG_ x_1 : 32|16@1+ (0.01,0) [0|135.0] "%VRef" Vector__XXX
 SG_ y_1 : 48|16@1- (0.01,0) [-100.0|100.0] "%W capability" Vector__XXX

BO_ 2150188288 INV_VoltWatt_Points_2_3_CMD: 8 HC
 SG_ x_2 : 0|16@1+ (0.01,0) [0|135.0] "%VRef" Vector__XXX
 SG_ y_2 : 16|16@1- (0.01,0) [-100.0|100.0] "%W capability" Vector__XXX
 SG_ x_3 : 32|16@1+ (0.01,0) [0|135.0] "%VRef" Vector__XXX
 SG_ y_3 : 48|16@1- (0.01,0) [-100.0|100.0] "%W capability" Vector__XXX

BO_ 2150188544 INV_VoltWatt_Points_4_5_CMD: 8 HC
 SG_ x_4 : 0|16@1+ (0.01,0) [0|135.0] "%VRef" Vector__XXX
 SG_ y_4 : 16|16@1- (0.01,0) [-100.0|100.0] "%W capability" Vector__XXX
 SG_ x_5 : 32|16@1+ (0.01,0) [0|135.0] "%VRef" Vector__XXX
 SG_ y_5 : 48|16@1- (0.01,0) [-100.0|100.0] "%W capability" Vector__XXX

BO_ 2150188800 INV_VoltWatt_Points_6_7_CMD: 8 HC
 SG_ x_6 : 0|16@1+ (0.01,0) [0|135.0] "%VRef" Vector__XXX
 SG_ y_6 : 16|16@1- (0.01,0) [-100.0|100.0] "%W capability" Vector__XXX
 SG_ x_7 : 32|16@1+ (0.01,0) [0|135.0] "%VRef" Vector__XXX
 SG_ y_7 : 48|16@1- (0.01,0) [-100.0|100.0] "%W capability" Vector__XXX

BO_ 2150189056 INV_VoltWatt_Points_8_9_CMD: 8 HC
 SG_ x_8 : 0|16@1+ (0.01,0) [0|135.0] "%VRef" Vector__XXX
 SG_ y_8 : 16|16@1- (0.01,0) [-100.0|100.0] "%W capability" Vector__XXX
 SG_ x_9 : 32|16@1+ (0.01,0) [0|135.0] "%VRef" Vector__XXX
 SG_ y_9 : 48|16@1- (0.01,0) [-100.0|100.0] "%W capability" Vector__XXX

BO_ 2149138432 INV_VoltWatt_CurveStatus_RSP: 2 INV
 SG_ CurveEnabled : 0|8@1+ (1,0) [0|255] "" Vector__XXX
 SG_ CurveUpdateStatus : 8|8@1+ (1,0) [0|255] "" Vector__XXX

BO_ 2149138688 INV_VoltWatt_Metadata_RSP: 2 INV
 SG_ CurveNumPoints : 0|8@1+ (1,0) [0|10] "" Vector__XXX
 SG_ yRefType : 8|8@1+ (1,0) [0|255] "" Vector__XXX

BO_ 2149138944 INV_VoltWatt_Timings_RSP: 8 INV
 SG_ OpenLoopTms : 0|16@1+ (0.01,0) [0|655.35] "%capability/s" Vector__XXX
 SG_ RampDecTms : 16|16@1+ (0.01,0) [0|655.35] "%capability/s" Vector__XXX
 SG_ RampIncTms : 32|16@1+ (0.01,0) [0|655.35] "%capability/s" Vector__XXX
 SG_ RampPT1 : 48|16@1+ (0.01,0) [0|655.35] "s" Vector__XXX

BO_ 2149139456 INV_VoltWatt_Points_0_1_RSP: 8 INV
 SG_ x_0 : 0|16@1+ (0.01,0) [0|135.0] "%VRef" Vector__XXX
 SG_ y_0 : 16|16@1- (0.01,0) [-100.0|100.0] "%W capability" Vector__XXX
 SG_ x_1 : 32|16@1+ (0.01,0) [0|135.0] "%VRef" Vector__XXX
 SG_ y_1 : 48|16@1- (0.01,0) [-100.0|100.0] "%W capability" Vector__XXX

BO_ 2149139712 INV_VoltWatt_Points_2_3_RSP: 8 INV
 SG_ x_2 : 0|16@1+ (0.01,0) [0|135.0] "%VRef" Vector__XXX
 SG_ y_2 : 16|16@1- (0.01,0) [-100.0|100.0] "%W capability" Vector__XXX
 SG_ x_3 : 32|16@1+ (0.01,0) [0|135.0] "%VRef" Vector__XXX
 SG_ y_3 : 48|16@1- (0.01,0) [-100.0|100.0] "%W capability" Vector__XXX

BO_ 2149139968 INV_VoltWatt_Points_4_5_RSP: 8 INV
 SG_ x_4 : 0|16@1+ (0.01,0) [0|135.0] "%VRef" Vector__XXX
 SG_ y_4 : 16|16@1- (0.01,0) [-100.0|100.0] "%W capability" Vector__XXX
 SG_ x_5 : 32|16@1+ (0.01,0) [0|135.0] "%VRef" Vector__XXX
 SG_ y_5 : 48|16@1- (0.01,0) [-100.0|100.0] "%W capability" Vector__XXX

BO_ 2149140224 INV_VoltWatt_Points_6_7_RSP: 8 INV
 SG_ x_6 : 0|16@1+ (0.01,0) [0|135.0] "%VRef" Vector__XXX
 SG_ y_6 : 16|16@1- (0.01,0) [-100.0|100.0] "%W capability" Vector__XXX
 SG_ x_7 : 32|16@1+ (0.01,0) [0|135.0] "%VRef" Vector__XXX
 SG_ y_7 : 48|16@1- (0.01,0) [-100.0|100.0] "%W capability" Vector__XXX

BO_ 2149140480 INV_VoltWatt_Points_8_9_RSP: 8 INV
 SG_ x_8 : 0|16@1+ (0.01,0) [0|135.0] "%VRef" Vector__XXX
 SG_ y_8 : 16|16@1- (0.01,0) [-100.0|100.0] "%W capability" Vector__XXX
 SG_ x_9 : 32|16@1+ (0.01,0) [0|135.0] "%VRef" Vector__XXX
 SG_ y_9 : 48|16@1- (0.01,0) [-100.0|100.0] "%W capability" Vector__XXX

BO_ 2150191104 INV_HFRTMayTrip_CurveStatus_CMD: 2 HC
 SG_ CurveEnabled : 0|8@1+ (1,0) [0|255] "" Vector__XXX
 SG_ CurveUpdateStatus : 8|8@1+ (1,0) [0|255] "" Vector__XXX

BO_ 2150191360 INV_HFRTMayTrip_Metadata_CMD: 1 HC
 SG_ CurveNumPoints : 0|8@1+ (1,0) [0|10] "" Vector__XXX

BO_ 2150191616 INV_HFRTMayTrip_Timings_CMD: 8 HC
 SG_ OpenLoopTms : 0|16@1+ (0.01,0) [0|655.35] "%capability/s" Vector__XXX
 SG_ RampDecTms : 16|16@1+ (0.01,0) [0|655.35] "%capability/s" Vector__XXX
 SG_ RampIncTms : 32|16@1+ (0.01,0) [0|655.35] "%capability/s" Vector__XXX
 SG_ RampPT1 : 48|16@1+ (0.01,0) [0|655.35] "s" Vector__XXX

BO_ 2150192128 INV_HFRTMayTrip_Points_0_1_CMD: 8 HC
 SG_ x_0 : 0|16@1+ (0.01,0) [0|655.35] "s" Vector__XXX
 SG_ y_0 : 16|16@1+ (0.01,0) [0|655.35] "Hz" Vector__XXX
 SG_ x_1 : 32|16@1+ (0.01,0) [0|655.35] "s" Vector__XXX
 SG_ y_1 : 48|16@1+ (0.01,0) [0|655.35] "Hz" Vector__XXX

BO_ 2150192384 INV_HFRTMayTrip_Points_2_3_CMD: 8 HC
 SG_ x_2 : 0|16@1+ (0.01,0) [0|655.35] "s" Vector__XXX
 SG_ y_2 : 16|16@1+ (0.01,0) [0|655.35] "Hz" Vector__XXX
 SG_ x_3 : 32|16@1+ (0.01,0) [0|655.35] "s" Vector__XXX
 SG_ y_3 : 48|16@1+ (0.01,0) [0|655.35] "Hz" Vector__XXX

BO_ 2150192640 INV_HFRTMayTrip_Points_4_5_CMD: 8 HC
 SG_ x_4 : 0|16@1+ (0.01,0) [0|655.35] "s" Vector__XXX
 SG_ y_4 : 16|16@1+ (0.01,0) [0|655.35] "Hz" Vector__XXX
 SG_ x_5 : 32|16@1+ (0.01,0) [0|655.35] "s" Vector__XXX
 SG_ y_5 : 48|16@1+ (0.01,0) [0|655.35] "Hz" Vector__XXX

BO_ 2150192896 INV_HFRTMayTrip_Points_6_7_CMD: 8 HC
 SG_ x_6 : 0|16@1+ (0.01,0) [0|655.35] "s" Vector__XXX
 SG_ y_6 : 16|16@1+ (0.01,0) [0|655.35] "Hz" Vector__XXX
 SG_ x_7 : 32|16@1+ (0.01,0) [0|655.35] "s" Vector__XXX
 SG_ y_7 : 48|16@1+ (0.01,0) [0|655.35] "Hz" Vector__XXX

BO_ 2150193152 INV_HFRTMayTrip_Points_8_9_CMD: 8 HC
 SG_ x_8 : 0|16@1+ (0.01,0) [0|655.35] "s" Vector__XXX
 SG_ y_8 : 16|16@1+ (0.01,0) [0|655.35] "Hz" Vector__XXX
 SG_ x_9 : 32|16@1+ (0.01,0) [0|655.35] "s" Vector__XXX
 SG_ y_9 : 48|16@1+ (0.01,0) [0|655.35] "Hz" Vector__XXX

BO_ 2149142528 INV_HFRTMayTrip_CurveStatus_RSP: 2 INV
 SG_ CurveEnabled : 0|8@1+ (1,0) [0|255] "" Vector__XXX
 SG_ CurveUpdateStatus : 8|8@1+ (1,0) [0|255] "" Vector__XXX

BO_ 2149142784 INV_HFRTMayTrip_Metadata_RSP: 1 INV
 SG_ CurveNumPoints : 0|8@1+ (1,0) [0|10] "" Vector__XXX

BO_ 2149143040 INV_HFRTMayTrip_Timings_RSP: 8 INV
 SG_ OpenLoopTms : 0|16@1+ (0.01,0) [0|655.35] "%capability/s" Vector__XXX
 SG_ RampDecTms : 16|16@1+ (0.01,0) [0|655.35] "%capability/s" Vector__XXX
 SG_ RampIncTms : 32|16@1+ (0.01,0) [0|655.35] "%capability/s" Vector__XXX
 SG_ RampPT1 : 48|16@1+ (0.01,0) [0|655.35] "s" Vector__XXX

BO_ 2149143552 INV_HFRTMayTrip_Points_0_1_RSP: 8 INV
 SG_ x_0 : 0|16@1+ (0.01,0) [0|655.35] "s" Vector__XXX
 SG_ y_0 : 16|16@1+ (0.01,0) [0|655.35] "Hz" Vector__XXX
 SG_ x_1 : 32|16@1+ (0.01,0) [0|655.35] "s" Vector__XXX
 SG_ y_1 : 48|16@1+ (0.01,0) [0|655.35] "Hz" Vector__XXX

BO_ 2149143808 INV_HFRTMayTrip_Points_2_3_RSP: 8 INV
 SG_ x_2 : 0|16@1+ (0.01,0) [0|655.35] "s" Vector__XXX
 SG_ y_2 : 16|16@1+ (0.01,0) [0|655.35] "Hz" Vector__XXX
 SG_ x_3 : 32|16@1+ (0.01,0) [0|655.35] "s" Vector__XXX
 SG_ y_3 : 48|16@1+ (0.01,0) [0|655.35] "Hz" Vector__XXX

BO_ 2149144064 INV_HFRTMayTrip_Points_4_5_RSP: 8 INV
 SG_ x_4 : 0|16@1+ (0.01,0) [0|655.35] "s" Vector__XXX
 SG_ y_4 : 16|16@1+ (0.01,0) [0|655.35] "Hz" Vector__XXX
 SG_ x_5 : 32|16@1+ (0.01,0) [0|655.35] "s" Vector__XXX
 SG_ y_5 : 48|16@1+ (0.01,0) [0|655.35] "Hz" Vector__XXX

BO_ 2149144320 INV_HFRTMayTrip_Points_6_7_RSP: 8 INV
 SG_ x_6 : 0|16@1+ (0.01,0) [0|655.35] "s" Vector__XXX
 SG_ y_6 : 16|16@1+ (0.01,0) [0|655.35] "Hz" Vector__XXX
 SG_ x_7 : 32|16@1+ (0.01,0) [0|655.35] "s" Vector__XXX
 SG_ y_7 : 48|16@1+ (0.01,0) [0|655.35] "Hz" Vector__XXX

BO_ 2149144576 INV_HFRTMayTrip_Points_8_9_RSP: 8 INV
 SG_ x_8 : 0|16@1+ (0.01,0) [0|655.35] "s" Vector__XXX
 SG_ y_8 : 16|16@1+ (0.01,0) [0|655.35] "Hz" Vector__XXX
 SG_ x_9 : 32|16@1+ (0.01,0) [0|655.35] "s" Vector__XXX
 SG_ y_9 : 48|16@1+ (0.01,0) [0|655.35] "Hz" Vector__XXX

BO_ 2150195200 INV_HFRTMustTrip_CurveStatus_CMD: 2 HC
 SG_ CurveEnabled : 0|8@1+ (1,0) [0|255] "" Vector__XXX
 SG_ CurveUpdateStatus : 8|8@1+ (1,0) [0|255] "" Vector__XXX

BO_ 2150195456 INV_HFRTMustTrip_Metadata_CMD: 1 HC
 SG_ CurveNumPoints : 0|8@1+ (1,0) [0|10] "" Vector__XXX

BO_ 2150195712 INV_HFRTMustTrip_Timings_CMD: 8 HC
 SG_ OpenLoopTms : 0|16@1+ (0.01,0) [0|655.35] "%capability/s" Vector__XXX
 SG_ RampDecTms : 16|16@1+ (0.01,0) [0|655.35] "%capability/s" Vector__XXX
 SG_ RampIncTms : 32|16@1+ (0.01,0) [0|655.35] "%capability/s" Vector__XXX
 SG_ RampPT1 : 48|16@1+ (0.01,0) [0|655.35] "s" Vector__XXX

BO_ 2150196224 INV_HFRTMustTrip_Points_0_1_CMD: 8 HC
 SG_ x_0 : 0|16@1+ (0.01,0) [0|655.35] "s" Vector__XXX
 SG_ y_0 : 16|16@1+ (0.01,0) [0|655.35] "Hz" Vector__XXX
 SG_ x_1 : 32|16@1+ (0.01,0) [0|655.35] "s" Vector__XXX
 SG_ y_1 : 48|16@1+ (0.01,0) [0|655.35] "Hz" Vector__XXX

BO_ 2150196480 INV_HFRTMustTrip_Points_2_3_CMD: 8 HC
 SG_ x_2 : 0|16@1+ (0.01,0) [0|655.35] "s" Vector__XXX
 SG_ y_2 : 16|16@1+ (0.01,0) [0|655.35] "Hz" Vector__XXX
 SG_ x_3 : 32|16@1+ (0.01,0) [0|655.35] "s" Vector__XXX
 SG_ y_3 : 48|16@1+ (0.01,0) [0|655.35] "Hz" Vector__XXX

BO_ 2150196736 INV_HFRTMustTrip_Points_4_5_CMD: 8 HC
 SG_ x_4 : 0|16@1+ (0.01,0) [0|655.35] "s" Vector__XXX
 SG_ y_4 : 16|16@1+ (0.01,0) [0|655.35] "Hz" Vector__XXX
 SG_ x_5 : 32|16@1+ (0.01,0) [0|655.35] "s" Vector__XXX
 SG_ y_5 : 48|16@1+ (0.01,0) [0|655.35] "Hz" Vector__XXX

BO_ 2150196992 INV_HFRTMustTrip_Points_6_7_CMD: 8 HC
 SG_ x_6 : 0|16@1+ (0.01,0) [0|655.35] "s" Vector__XXX
 SG_ y_6 : 16|16@1+ (0.01,0) [0|655.35] "Hz" Vector__XXX
 SG_ x_7 : 32|16@1+ (0.01,0) [0|655.35] "s" Vector__XXX
 SG_ y_7 : 48|16@1+ (0.01,0) [0|655.35] "Hz" Vector__XXX

BO_ 2150197248 INV_HFRTMustTrip_Points_8_9_CMD: 8 HC
 SG_ x_8 : 0|16@1+ (0.01,0) [0|655.35] "s" Vector__XXX
 SG_ y_8 : 16|16@1+ (0.01,0) [0|655.35] "Hz" Vector__XXX
 SG_ x_9 : 32|16@1+ (0.01,0) [0|655.35] "s" Vector__XXX
 SG_ y_9 : 48|16@1+ (0.01,0) [0|655.35] "Hz" Vector__XXX

BO_ 2149146624 INV_HFRTMustTrip_CurveStatus_RSP: 2 INV
 SG_ CurveEnabled : 0|8@1+ (1,0) [0|255] "" Vector__XXX
 SG_ CurveUpdateStatus : 8|8@1+ (1,0) [0|255] "" Vector__XXX

BO_ 2149146880 INV_HFRTMustTrip_Metadata_RSP: 1 INV
 SG_ CurveNumPoints : 0|8@1+ (1,0) [0|10] "" Vector__XXX

BO_ 2149147136 INV_HFRTMustTrip_Timings_RSP: 8 INV
 SG_ OpenLoopTms : 0|16@1+ (0.01,0) [0|655.35] "%capability/s" Vector__XXX
 SG_ RampDecTms : 16|16@1+ (0.01,0) [0|655.35] "%capability/s" Vector__XXX
 SG_ RampIncTms : 32|16@1+ (0.01,0) [0|655.35] "%capability/s" Vector__XXX
 SG_ RampPT1 : 48|16@1+ (0.01,0) [0|655.35] "s" Vector__XXX

BO_ 2149147648 INV_HFRTMustTrip_Points_0_1_RSP: 8 INV
 SG_ x_0 : 0|16@1+ (0.01,0) [0|655.35] "s" Vector__XXX
 SG_ y_0 : 16|16@1+ (0.01,0) [0|655.35] "Hz" Vector__XXX
 SG_ x_1 : 32|16@1+ (0.01,0) [0|655.35] "s" Vector__XXX
 SG_ y_1 : 48|16@1+ (0.01,0) [0|655.35] "Hz" Vector__XXX

BO_ 2149147904 INV_HFRTMustTrip_Points_2_3_RSP: 8 INV
 SG_ x_2 : 0|16@1+ (0.01,0) [0|655.35] "s" Vector__XXX
 SG_ y_2 : 16|16@1+ (0.01,0) [0|655.35] "Hz" Vector__XXX
 SG_ x_3 : 32|16@1+ (0.01,0) [0|655.35] "s" Vector__XXX
 SG_ y_3 : 48|16@1+ (0.01,0) [0|655.35] "Hz" Vector__XXX

BO_ 2149148160 INV_HFRTMustTrip_Points_4_5_RSP: 8 INV
 SG_ x_4 : 0|16@1+ (0.01,0) [0|655.35] "s" Vector__XXX
 SG_ y_4 : 16|16@1+ (0.01,0) [0|655.35] "Hz" Vector__XXX
 SG_ x_5 : 32|16@1+ (0.01,0) [0|655.35] "s" Vector__XXX
 SG_ y_5 : 48|16@1+ (0.01,0) [0|655.35] "Hz" Vector__XXX

BO_ 2149148416 INV_HFRTMustTrip_Points_6_7_RSP: 8 INV
 SG_ x_6 : 0|16@1+ (0.01,0) [0|655.35] "s" Vector__XXX
 SG_ y_6 : 16|16@1+ (0.01,0) [0|655.35] "Hz" Vector__XXX
 SG_ x_7 : 32|16@1+ (0.01,0) [0|655.35] "s" Vector__XXX
 SG_ y_7 : 48|16@1+ (0.01,0) [0|655.35] "Hz" Vector__XXX

BO_ 2149148672 INV_HFRTMustTrip_Points_8_9_RSP: 8 INV
 SG_ x_8 : 0|16@1+ (0.01,0) [0|655.35] "s" Vector__XXX
 SG_ y_8 : 16|16@1+ (0.01,0) [0|655.35] "Hz" Vector__XXX
 SG_ x_9 : 32|16@1+ (0.01,0) [0|655.35] "s" Vector__XXX
 SG_ y_9 : 48|16@1+ (0.01,0) [0|655.35] "Hz" Vector__XXX

BO_ 2150199296 INV_LFRTMayTrip_CurveStatus_CMD: 2 HC
 SG_ CurveEnabled : 0|8@1+ (1,0) [0|255] "" Vector__XXX
 SG_ CurveUpdateStatus : 8|8@1+ (1,0) [0|255] "" Vector__XXX

BO_ 2150199552 INV_LFRTMayTrip_Metadata_CMD: 1 HC
 SG_ CurveNumPoints : 0|8@1+ (1,0) [0|10] "" Vector__XXX

BO_ 2150199808 INV_LFRTMayTrip_Timings_CMD: 8 HC
 SG_ OpenLoopTms : 0|16@1+ (0.01,0) [0|655.35] "%capability/s" Vector__XXX
 SG_ RampDecTms : 16|16@1+ (0.01,0) [0|655.35] "%capability/s" Vector__XXX
 SG_ RampIncTms : 32|16@1+ (0.01,0) [0|655.35] "%capability/s" Vector__XXX
 SG_ RampPT1 : 48|16@1+ (0.01,0) [0|655.35] "s" Vector__XXX

BO_ 2150200320 INV_LFRTMayTrip_Points_0_1_CMD: 8 HC
 SG_ x_0 : 0|16@1+ (0.01,0) [0|655.35] "s" Vector__XXX
 SG_ y_0 : 16|16@1+ (0.01,0) [0|655.35] "Hz" Vector__XXX
 SG_ x_1 : 32|16@1+ (0.01,0) [0|655.35] "s" Vector__XXX
 SG_ y_1 : 48|16@1+ (0.01,0) [0|655.35] "Hz" Vector__XXX

BO_ 2150200576 INV_LFRTMayTrip_Points_2_3_CMD: 8 HC
 SG_ x_2 : 0|16@1+ (0.01,0) [0|655.35] "s" Vector__XXX
 SG_ y_2 : 16|16@1+ (0.01,0) [0|655.35] "Hz" Vector__XXX
 SG_ x_3 : 32|16@1+ (0.01,0) [0|655.35] "s" Vector__XXX
 SG_ y_3 : 48|16@1+ (0.01,0) [0|655.35] "Hz" Vector__XXX

BO_ 2150200832 INV_LFRTMayTrip_Points_4_5_CMD: 8 HC
 SG_ x_4 : 0|16@1+ (0.01,0) [0|655.35] "s" Vector__XXX
 SG_ y_4 : 16|16@1+ (0.01,0) [0|655.35] "Hz" Vector__XXX
 SG_ x_5 : 32|16@1+ (0.01,0) [0|655.35] "s" Vector__XXX
 SG_ y_5 : 48|16@1+ (0.01,0) [0|655.35] "Hz" Vector__XXX

BO_ 2150201088 INV_LFRTMayTrip_Points_6_7_CMD: 8 HC
 SG_ x_6 : 0|16@1+ (0.01,0) [0|655.35] "s" Vector__XXX
 SG_ y_6 : 16|16@1+ (0.01,0) [0|655.35] "Hz" Vector__XXX
 SG_ x_7 : 32|16@1+ (0.01,0) [0|655.35] "s" Vector__XXX
 SG_ y_7 : 48|16@1+ (0.01,0) [0|655.35] "Hz" Vector__XXX

BO_ 2150201344 INV_LFRTMayTrip_Points_8_9_CMD: 8 HC
 SG_ x_8 : 0|16@1+ (0.01,0) [0|655.35] "s" Vector__XXX
 SG_ y_8 : 16|16@1+ (0.01,0) [0|655.35] "Hz" Vector__XXX
 SG_ x_9 : 32|16@1+ (0.01,0) [0|655.35] "s" Vector__XXX
 SG_ y_9 : 48|16@1+ (0.01,0) [0|655.35] "Hz" Vector__XXX

BO_ 2149150720 INV_LFRTMayTrip_CurveStatus_RSP: 2 INV
 SG_ CurveEnabled : 0|8@1+ (1,0) [0|255] "" Vector__XXX
 SG_ CurveUpdateStatus : 8|8@1+ (1,0) [0|255] "" Vector__XXX

BO_ 2149150976 INV_LFRTMayTrip_Metadata_RSP: 1 INV
 SG_ CurveNumPoints : 0|8@1+ (1,0) [0|10] "" Vector__XXX

BO_ 2149151232 INV_LFRTMayTrip_Timings_RSP: 8 INV
 SG_ OpenLoopTms : 0|16@1+ (0.01,0) [0|655.35] "%capability/s" Vector__XXX
 SG_ RampDecTms : 16|16@1+ (0.01,0) [0|655.35] "%capability/s" Vector__XXX
 SG_ RampIncTms : 32|16@1+ (0.01,0) [0|655.35] "%capability/s" Vector__XXX
 SG_ RampPT1 : 48|16@1+ (0.01,0) [0|655.35] "s" Vector__XXX

BO_ 2149151744 INV_LFRTMayTrip_Points_0_1_RSP: 8 INV
 SG_ x_0 : 0|16@1+ (0.01,0) [0|655.35] "s" Vector__XXX
 SG_ y_0 : 16|16@1+ (0.01,0) [0|655.35] "Hz" Vector__XXX
 SG_ x_1 : 32|16@1+ (0.01,0) [0|655.35] "s" Vector__XXX
 SG_ y_1 : 48|16@1+ (0.01,0) [0|655.35] "Hz" Vector__XXX

BO_ 2149152000 INV_LFRTMayTrip_Points_2_3_RSP: 8 INV
 SG_ x_2 : 0|16@1+ (0.01,0) [0|655.35] "s" Vector__XXX
 SG_ y_2 : 16|16@1+ (0.01,0) [0|655.35] "Hz" Vector__XXX
 SG_ x_3 : 32|16@1+ (0.01,0) [0|655.35] "s" Vector__XXX
 SG_ y_3 : 48|16@1+ (0.01,0) [0|655.35] "Hz" Vector__XXX

BO_ 2149152256 INV_LFRTMayTrip_Points_4_5_RSP: 8 INV
 SG_ x_4 : 0|16@1+ (0.01,0) [0|655.35] "s" Vector__XXX
 SG_ y_4 : 16|16@1+ (0.01,0) [0|655.35] "Hz" Vector__XXX
 SG_ x_5 : 32|16@1+ (0.01,0) [0|655.35] "s" Vector__XXX
 SG_ y_5 : 48|16@1+ (0.01,0) [0|655.35] "Hz" Vector__XXX

BO_ 2149152512 INV_LFRTMayTrip_Points_6_7_RSP: 8 INV
 SG_ x_6 : 0|16@1+ (0.01,0) [0|655.35] "s" Vector__XXX
 SG_ y_6 : 16|16@1+ (0.01,0) [0|655.35] "Hz" Vector__XXX
 SG_ x_7 : 32|16@1+ (0.01,0) [0|655.35] "s" Vector__XXX
 SG_ y_7 : 48|16@1+ (0.01,0) [0|655.35] "Hz" Vector__XXX

BO_ 2149152768 INV_LFRTMayTrip_Points_8_9_RSP: 8 INV
 SG_ x_8 : 0|16@1+ (0.01,0) [0|655.35] "s" Vector__XXX
 SG_ y_8 : 16|16@1+ (0.01,0) [0|655.35] "Hz" Vector__XXX
 SG_ x_9 : 32|16@1+ (0.01,0) [0|655.35] "s" Vector__XXX
 SG_ y_9 : 48|16@1+ (0.01,0) [0|655.35] "Hz" Vector__XXX

BO_ 2150203392 INV_LFRTMustTrip_CurveStatus_CMD: 2 HC
 SG_ CurveEnabled : 0|8@1+ (1,0) [0|255] "" Vector__XXX
 SG_ CurveUpdateStatus : 8|8@1+ (1,0) [0|255] "" Vector__XXX

BO_ 2150203648 INV_LFRTMustTrip_Metadata_CMD: 1 HC
 SG_ CurveNumPoints : 0|8@1+ (1,0) [0|10] "" Vector__XXX

BO_ 2150203904 INV_LFRTMustTrip_Timings_CMD: 8 HC
 SG_ OpenLoopTms : 0|16@1+ (0.01,0) [0|655.35] "%capability/s" Vector__XXX
 SG_ RampDecTms : 16|16@1+ (0.01,0) [0|655.35] "%capability/s" Vector__XXX
 SG_ RampIncTms : 32|16@1+ (0.01,0) [0|655.35] "%capability/s" Vector__XXX
 SG_ RampPT1 : 48|16@1+ (0.01,0) [0|655.35] "s" Vector__XXX

BO_ 2150204416 INV_LFRTMustTrip_Points_0_1_CMD: 8 HC
 SG_ x_0 : 0|16@1+ (0.01,0) [0|655.35] "s" Vector__XXX
 SG_ y_0 : 16|16@1+ (0.01,0) [0|655.35] "Hz" Vector__XXX
 SG_ x_1 : 32|16@1+ (0.01,0) [0|655.35] "s" Vector__XXX
 SG_ y_1 : 48|16@1+ (0.01,0) [0|655.35] "Hz" Vector__XXX

BO_ 2150204672 INV_LFRTMustTrip_Points_2_3_CMD: 8 HC
 SG_ x_2 : 0|16@1+ (0.01,0) [0|655.35] "s" Vector__XXX
 SG_ y_2 : 16|16@1+ (0.01,0) [0|655.35] "Hz" Vector__XXX
 SG_ x_3 : 32|16@1+ (0.01,0) [0|655.35] "s" Vector__XXX
 SG_ y_3 : 48|16@1+ (0.01,0) [0|655.35] "Hz" Vector__XXX

BO_ 2150204928 INV_LFRTMustTrip_Points_4_5_CMD: 8 HC
 SG_ x_4 : 0|16@1+ (0.01,0) [0|655.35] "s" Vector__XXX
 SG_ y_4 : 16|16@1+ (0.01,0) [0|655.35] "Hz" Vector__XXX
 SG_ x_5 : 32|16@1+ (0.01,0) [0|655.35] "s" Vector__XXX
 SG_ y_5 : 48|16@1+ (0.01,0) [0|655.35] "Hz" Vector__XXX

BO_ 2150205184 INV_LFRTMustTrip_Points_6_7_CMD: 8 HC
 SG_ x_6 : 0|16@1+ (0.01,0) [0|655.35] "s" Vector__XXX
 SG_ y_6 : 16|16@1+ (0.01,0) [0|655.35] "Hz" Vector__XXX
 SG_ x_7 : 32|16@1+ (0.01,0) [0|655.35] "s" Vector__XXX
 SG_ y_7 : 48|16@1+ (0.01,0) [0|655.35] "Hz" Vector__XXX

BO_ 2150205440 INV_LFRTMustTrip_Points_8_9_CMD: 8 HC
 SG_ x_8 : 0|16@1+ (0.01,0) [0|655.35] "s" Vector__XXX
 SG_ y_8 : 16|16@1+ (0.01,0) [0|655.35] "Hz" Vector__XXX
 SG_ x_9 : 32|16@1+ (0.01,0) [0|655.35] "s" Vector__XXX
 SG_ y_9 : 48|16@1+ (0.01,0) [0|655.35] "Hz" Vector__XXX

BO_ 2149154816 INV_LFRTMustTrip_CurveStatus_RSP: 2 INV
 SG_ CurveEnabled : 0|8@1+ (1,0) [0|255] "" Vector__XXX
 SG_ CurveUpdateStatus : 8|8@1+ (1,0) [0|255] "" Vector__XXX

BO_ 2149155072 INV_LFRTMustTrip_Metadata_RSP: 1 INV
 SG_ CurveNumPoints : 0|8@1+ (1,0) [0|10] "" Vector__XXX

BO_ 2149155328 INV_LFRTMustTrip_Timings_RSP: 8 INV
 SG_ OpenLoopTms : 0|16@1+ (0.01,0) [0|655.35] "%capability/s" Vector__XXX
 SG_ RampDecTms : 16|16@1+ (0.01,0) [0|655.35] "%capability/s" Vector__XXX
 SG_ RampIncTms : 32|16@1+ (0.01,0) [0|655.35] "%capability/s" Vector__XXX
 SG_ RampPT1 : 48|16@1+ (0.01,0) [0|655.35] "s" Vector__XXX

BO_ 2149155840 INV_LFRTMustTrip_Points_0_1_RSP: 8 INV
 SG_ x_0 : 0|16@1+ (0.01,0) [0|655.35] "s" Vector__XXX
 SG_ y_0 : 16|16@1+ (0.01,0) [0|655.35] "Hz" Vector__XXX
 SG_ x_1 : 32|16@1+ (0.01,0) [0|655.35] "s" Vector__XXX
 SG_ y_1 : 48|16@1+ (0.01,0) [0|655.35] "Hz" Vector__XXX

BO_ 2149156096 INV_LFRTMustTrip_Points_2_3_RSP: 8 INV
 SG_ x_2 : 0|16@1+ (0.01,0) [0|655.35] "s" Vector__XXX
 SG_ y_2 : 16|16@1+ (0.01,0) [0|655.35] "Hz" Vector__XXX
 SG_ x_3 : 32|16@1+ (0.01,0) [0|655.35] "s" Vector__XXX
 SG_ y_3 : 48|16@1+ (0.01,0) [0|655.35] "Hz" Vector__XXX

BO_ 2149156352 INV_LFRTMustTrip_Points_4_5_RSP: 8 INV
 SG_ x_4 : 0|16@1+ (0.01,0) [0|655.35] "s" Vector__XXX
 SG_ y_4 : 16|16@1+ (0.01,0) [0|655.35] "Hz" Vector__XXX
 SG_ x_5 : 32|16@1+ (0.01,0) [0|655.35] "s" Vector__XXX
 SG_ y_5 : 48|16@1+ (0.01,0) [0|655.35] "Hz" Vector__XXX

BO_ 2149156608 INV_LFRTMustTrip_Points_6_7_RSP: 8 INV
 SG_ x_6 : 0|16@1+ (0.01,0) [0|655.35] "s" Vector__XXX
 SG_ y_6 : 16|16@1+ (0.01,0) [0|655.35] "Hz" Vector__XXX
 SG_ x_7 : 32|16@1+ (0.01,0) [0|655.35] "s" Vector__XXX
 SG_ y_7 : 48|16@1+ (0.01,0) [0|655.35] "Hz" Vector__XXX

BO_ 2149156864 INV_LFRTMustTrip_Points_8_9_RSP: 8 INV
 SG_ x_8 : 0|16@1+ (0.01,0) [0|655.35] "s" Vector__XXX
 SG_ y_8 : 16|16@1+ (0.01,0) [0|655.35] "Hz" Vector__XXX
 SG_ x_9 : 32|16@1+ (0.01,0) [0|655.35] "s" Vector__XXX
 SG_ y_9 : 48|16@1+ (0.01,0) [0|655.35] "Hz" Vector__XXX

BO_ 2150207488 INV_HVRTMayTrip_CurveStatus_CMD: 2 HC
 SG_ CurveEnabled : 0|8@1+ (1,0) [0|255] "" Vector__XXX
 SG_ CurveUpdateStatus : 8|8@1+ (1,0) [0|255] "" Vector__XXX

BO_ 2150207744 INV_HVRTMayTrip_Metadata_CMD: 1 HC
 SG_ CurveNumPoints : 0|8@1+ (1,0) [0|10] "" Vector__XXX

BO_ 2150208000 INV_HVRTMayTrip_Timings_CMD: 8 HC
 SG_ OpenLoopTms : 0|16@1+ (0.01,0) [0|655.35] "%capability/s" Vector__XXX
 SG_ RampDecTms : 16|16@1+ (0.01,0) [0|655.35] "%capability/s" Vector__XXX
 SG_ RampIncTms : 32|16@1+ (0.01,0) [0|655.35] "%capability/s" Vector__XXX
 SG_ RampPT1 : 48|16@1+ (0.01,0) [0|655.35] "s" Vector__XXX

BO_ 2150208512 INV_HVRTMayTrip_Points_0_1_CMD: 8 HC
 SG_ x_0 : 0|16@1+ (0.01,0) [0|655.35] "s" Vector__XXX
 SG_ y_0 : 16|16@1+ (0.01,0) [0|135.0] "%VRef" Vector__XXX
 SG_ x_1 : 32|16@1+ (0.01,0) [0|655.35] "s" Vector__XXX
 SG_ y_1 : 48|16@1+ (0.01,0) [0|135.0] "%VRef" Vector__XXX

BO_ 2150208768 INV_HVRTMayTrip_Points_2_3_CMD: 8 HC
 SG_ x_2 : 0|16@1+ (0.01,0) [0|655.35] "s" Vector__XXX
 SG_ y_2 : 16|16@1+ (0.01,0) [0|135.0] "%VRef" Vector__XXX
 SG_ x_3 : 32|16@1+ (0.01,0) [0|655.35] "s" Vector__XXX
 SG_ y_3 : 48|16@1+ (0.01,0) [0|135.0] "%VRef" Vector__XXX

BO_ 2150209024 INV_HVRTMayTrip_Points_4_5_CMD: 8 HC
 SG_ x_4 : 0|16@1+ (0.01,0) [0|655.35] "s" Vector__XXX
 SG_ y_4 : 16|16@1+ (0.01,0) [0|135.0] "%VRef" Vector__XXX
 SG_ x_5 : 32|16@1+ (0.01,0) [0|655.35] "s" Vector__XXX
 SG_ y_5 : 48|16@1+ (0.01,0) [0|135.0] "%VRef" Vector__XXX

BO_ 2150209280 INV_HVRTMayTrip_Points_6_7_CMD: 8 HC
 SG_ x_6 : 0|16@1+ (0.01,0) [0|655.35] "s" Vector__XXX
 SG_ y_6 : 16|16@1+ (0.01,0) [0|135.0] "%VRef" Vector__XXX
 SG_ x_7 : 32|16@1+ (0.01,0) [0|655.35] "s" Vector__XXX
 SG_ y_7 : 48|16@1+ (0.01,0) [0|135.0] "%VRef" Vector__XXX

BO_ 2150209536 INV_HVRTMayTrip_Points_8_9_CMD: 8 HC
 SG_ x_8 : 0|16@1+ (0.01,0) [0|655.35] "s" Vector__XXX
 SG_ y_8 : 16|16@1+ (0.01,0) [0|135.0] "%VRef" Vector__XXX
 SG_ x_9 : 32|16@1+ (0.01,0) [0|655.35] "s" Vector__XXX
 SG_ y_9 : 48|16@1+ (0.01,0) [0|135.0] "%VRef" Vector__XXX

BO_ 2149158912 INV_HVRTMayTrip_CurveStatus_RSP: 2 INV
 SG_ CurveEnabled : 0|8@1+ (1,0) [0|255] "" Vector__XXX
 SG_ CurveUpdateStatus : 8|8@1+ (1,0) [0|255] "" Vector__XXX

BO_ 2149159168 INV_HVRTMayTrip_Metadata_RSP: 1 INV
 SG_ CurveNumPoints : 0|8@1+ (1,0) [0|10] "" Vector__XXX

BO_ 2149159424 INV_HVRTMayTrip_Timings_RSP: 8 INV
 SG_ OpenLoopTms : 0|16@1+ (0.01,0) [0|655.35] "%capability/s" Vector__XXX
 SG_ RampDecTms : 16|16@1+ (0.01,0) [0|655.35] "%capability/s" Vector__XXX
 SG_ RampIncTms : 32|16@1+ (0.01,0) [0|655.35] "%capability/s" Vector__XXX
 SG_ RampPT1 : 48|16@1+ (0.01,0) [0|655.35] "s" Vector__XXX

BO_ 2149159936 INV_HVRTMayTrip_Points_0_1_RSP: 8 INV
 SG_ x_0 : 0|16@1+ (0.01,0) [0|655.35] "s" Vector__XXX
 SG_ y_0 : 16|16@1+ (0.01,0) [0|135.0] "%VRef" Vector__XXX
 SG_ x_1 : 32|16@1+ (0.01,0) [0|655.35] "s" Vector__XXX
 SG_ y_1 : 48|16@1+ (0.01,0) [0|135.0] "%VRef" Vector__XXX

BO_ 2149160192 INV_HVRTMayTrip_Points_2_3_RSP: 8 INV
 SG_ x_2 : 0|16@1+ (0.01,0) [0|655.35] "s" Vector__XXX
 SG_ y_2 : 16|16@1+ (0.01,0) [0|135.0] "%VRef" Vector__XXX
 SG_ x_3 : 32|16@1+ (0.01,0) [0|655.35] "s" Vector__XXX
 SG_ y_3 : 48|16@1+ (0.01,0) [0|135.0] "%VRef" Vector__XXX

BO_ 2149160448 INV_HVRTMayTrip_Points_4_5_RSP: 8 INV
 SG_ x_4 : 0|16@1+ (0.01,0) [0|655.35] "s" Vector__XXX
 SG_ y_4 : 16|16@1+ (0.01,0) [0|135.0] "%VRef" Vector__XXX
 SG_ x_5 : 32|16@1+ (0.01,0) [0|655.35] "s" Vector__XXX
 SG_ y_5 : 48|16@1+ (0.01,0) [0|135.0] "%VRef" Vector__XXX

BO_ 2149160704 INV_HVRTMayTrip_Points_6_7_RSP: 8 INV
 SG_ x_6 : 0|16@1+ (0.01,0) [0|655.35] "s" Vector__XXX
 SG_ y_6 : 16|16@1+ (0.01,0) [0|135.0] "%VRef" Vector__XXX
 SG_ x_7 : 32|16@1+ (0.01,0) [0|655.35] "s" Vector__XXX
 SG_ y_7 : 48|16@1+ (0.01,0) [0|135.0] "%VRef" Vector__XXX

BO_ 2149160960 INV_HVRTMayTrip_Points_8_9_RSP: 8 INV
 SG_ x_8 : 0|16@1+ (0.01,0) [0|655.35] "s" Vector__XXX
 SG_ y_8 : 16|16@1+ (0.01,0) [0|135.0] "%VRef" Vector__XXX
 SG_ x_9 : 32|16@1+ (0.01,0) [0|655.35] "s" Vector__XXX
 SG_ y_9 : 48|16@1+ (0.01,0) [0|135.0] "%VRef" Vector__XXX

BO_ 2150211584 INV_HVRTMC_CurveStatus_CMD: 2 HC
 SG_ CurveEnabled : 0|8@1+ (1,0) [0|255] "" Vector__XXX
 SG_ CurveUpdateStatus : 8|8@1+ (1,0) [0|255] "" Vector__XXX

BO_ 2150211840 INV_HVRTMC_Metadata_CMD: 1 HC
 SG_ CurveNumPoints : 0|8@1+ (1,0) [0|10] "" Vector__XXX

BO_ 2150212096 INV_HVRTMC_Timings_CMD: 8 HC
 SG_ OpenLoopTms : 0|16@1+ (0.01,0) [0|655.35] "%capability/s" Vector__XXX
 SG_ RampDecTms : 16|16@1+ (0.01,0) [0|655.35] "%capability/s" Vector__XXX
 SG_ RampIncTms : 32|16@1+ (0.01,0) [0|655.35] "%capability/s" Vector__XXX
 SG_ RampPT1 : 48|16@1+ (0.01,0) [0|655.35] "s" Vector__XXX

BO_ 2150212608 INV_HVRTMC_Points_0_1_CMD: 8 HC
 SG_ x_0 : 0|16@1+ (0.01,0) [0|655.35] "s" Vector__XXX
 SG_ y_0 : 16|16@1+ (0.01,0) [0|135.0] "%VRef" Vector__XXX
 SG_ x_1 : 32|16@1+ (0.01,0) [0|655.35] "s" Vector__XXX
 SG_ y_1 : 48|16@1+ (0.01,0) [0|135.0] "%VRef" Vector__XXX

BO_ 2150212864 INV_HVRTMC_Points_2_3_CMD: 8 HC
 SG_ x_2 : 0|16@1+ (0.01,0) [0|655.35] "s" Vector__XXX
 SG_ y_2 : 16|16@1+ (0.01,0) [0|135.0] "%VRef" Vector__XXX
 SG_ x_3 : 32|16@1+ (0.01,0) [0|655.35] "s" Vector__XXX
 SG_ y_3 : 48|16@1+ (0.01,0) [0|135.0] "%VRef" Vector__XXX

BO_ 2150213120 INV_HVRTMC_Points_4_5_CMD: 8 HC
 SG_ x_4 : 0|16@1+ (0.01,0) [0|655.35] "s" Vector__XXX
 SG_ y_4 : 16|16@1+ (0.01,0) [0|135.0] "%VRef" Vector__XXX
 SG_ x_5 : 32|16@1+ (0.01,0) [0|655.35] "s" Vector__XXX
 SG_ y_5 : 48|16@1+ (0.01,0) [0|135.0] "%VRef" Vector__XXX

BO_ 2150213376 INV_HVRTMC_Points_6_7_CMD: 8 HC
 SG_ x_6 : 0|16@1+ (0.01,0) [0|655.35] "s" Vector__XXX
 SG_ y_6 : 16|16@1+ (0.01,0) [0|135.0] "%VRef" Vector__XXX
 SG_ x_7 : 32|16@1+ (0.01,0) [0|655.35] "s" Vector__XXX
 SG_ y_7 : 48|16@1+ (0.01,0) [0|135.0] "%VRef" Vector__XXX

BO_ 2150213632 INV_HVRTMC_Points_8_9_CMD: 8 HC
 SG_ x_8 : 0|16@1+ (0.01,0) [0|655.35] "s" Vector__XXX
 SG_ y_8 : 16|16@1+ (0.01,0) [0|135.0] "%VRef" Vector__XXX
 SG_ x_9 : 32|16@1+ (0.01,0) [0|655.35] "s" Vector__XXX
 SG_ y_9 : 48|16@1+ (0.01,0) [0|135.0] "%VRef" Vector__XXX

BO_ 2149163008 INV_HVRTMC_CurveStatus_RSP: 2 INV
 SG_ CurveEnabled : 0|8@1+ (1,0) [0|255] "" Vector__XXX
 SG_ CurveUpdateStatus : 8|8@1+ (1,0) [0|255] "" Vector__XXX

BO_ 2149163264 INV_HVRTMC_Metadata_RSP: 1 INV
 SG_ CurveNumPoints : 0|8@1+ (1,0) [0|10] "" Vector__XXX

BO_ 2149163520 INV_HVRTMC_Timings_RSP: 8 INV
 SG_ OpenLoopTms : 0|16@1+ (0.01,0) [0|655.35] "%capability/s" Vector__XXX
 SG_ RampDecTms : 16|16@1+ (0.01,0) [0|655.35] "%capability/s" Vector__XXX
 SG_ RampIncTms : 32|16@1+ (0.01,0) [0|655.35] "%capability/s" Vector__XXX
 SG_ RampPT1 : 48|16@1+ (0.01,0) [0|655.35] "s" Vector__XXX

BO_ 2149164032 INV_HVRTMC_Points_0_1_RSP: 8 INV
 SG_ x_0 : 0|16@1+ (0.01,0) [0|655.35] "s" Vector__XXX
 SG_ y_0 : 16|16@1+ (0.01,0) [0|135.0] "%VRef" Vector__XXX
 SG_ x_1 : 32|16@1+ (0.01,0) [0|655.35] "s" Vector__XXX
 SG_ y_1 : 48|16@1+ (0.01,0) [0|135.0] "%VRef" Vector__XXX

BO_ 2149164288 INV_HVRTMC_Points_2_3_RSP: 8 INV
 SG_ x_2 : 0|16@1+ (0.01,0) [0|655.35] "s" Vector__XXX
 SG_ y_2 : 16|16@1+ (0.01,0) [0|135.0] "%VRef" Vector__XXX
 SG_ x_3 : 32|16@1+ (0.01,0) [0|655.35] "s" Vector__XXX
 SG_ y_3 : 48|16@1+ (0.01,0) [0|135.0] "%VRef" Vector__XXX

BO_ 2149164544 INV_HVRTMC_Points_4_5_RSP: 8 INV
 SG_ x_4 : 0|16@1+ (0.01,0) [0|655.35] "s" Vector__XXX
 SG_ y_4 : 16|16@1+ (0.01,0) [0|135.0] "%VRef" Vector__XXX
 SG_ x_5 : 32|16@1+ (0.01,0) [0|655.35] "s" Vector__XXX
 SG_ y_5 : 48|16@1+ (0.01,0) [0|135.0] "%VRef" Vector__XXX

BO_ 2149164800 INV_HVRTMC_Points_6_7_RSP: 8 INV
 SG_ x_6 : 0|16@1+ (0.01,0) [0|655.35] "s" Vector__XXX
 SG_ y_6 : 16|16@1+ (0.01,0) [0|135.0] "%VRef" Vector__XXX
 SG_ x_7 : 32|16@1+ (0.01,0) [0|655.35] "s" Vector__XXX
 SG_ y_7 : 48|16@1+ (0.01,0) [0|135.0] "%VRef" Vector__XXX

BO_ 2149165056 INV_HVRTMC_Points_8_9_RSP: 8 INV
 SG_ x_8 : 0|16@1+ (0.01,0) [0|655.35] "s" Vector__XXX
 SG_ y_8 : 16|16@1+ (0.01,0) [0|135.0] "%VRef" Vector__XXX
 SG_ x_9 : 32|16@1+ (0.01,0) [0|655.35] "s" Vector__XXX
 SG_ y_9 : 48|16@1+ (0.01,0) [0|135.0] "%VRef" Vector__XXX

BO_ 2150215680 INV_HVRTMustTrip_CurveStatus_CMD: 2 HC
 SG_ CurveEnabled : 0|8@1+ (1,0) [0|255] "" Vector__XXX
 SG_ CurveUpdateStatus : 8|8@1+ (1,0) [0|255] "" Vector__XXX

BO_ 2150215936 INV_HVRTMustTrip_Metadata_CMD: 1 HC
 SG_ CurveNumPoints : 0|8@1+ (1,0) [0|10] "" Vector__XXX

BO_ 2150216192 INV_HVRTMustTrip_Timings_CMD: 8 HC
 SG_ OpenLoopTms : 0|16@1+ (0.01,0) [0|655.35] "%capability/s" Vector__XXX
 SG_ RampDecTms : 16|16@1+ (0.01,0) [0|655.35] "%capability/s" Vector__XXX
 SG_ RampIncTms : 32|16@1+ (0.01,0) [0|655.35] "%capability/s" Vector__XXX
 SG_ RampPT1 : 48|16@1+ (0.01,0) [0|655.35] "s" Vector__XXX

BO_ 2150216704 INV_HVRTMustTrip_Points_0_1_CMD: 8 HC
 SG_ x_0 : 0|16@1+ (0.01,0) [0|655.35] "s" Vector__XXX
 SG_ y_0 : 16|16@1+ (0.01,0) [0|135.0] "%VRef" Vector__XXX
 SG_ x_1 : 32|16@1+ (0.01,0) [0|655.35] "s" Vector__XXX
 SG_ y_1 : 48|16@1+ (0.01,0) [0|135.0] "%VRef" Vector__XXX

BO_ 2150216960 INV_HVRTMustTrip_Points_2_3_CMD: 8 HC
 SG_ x_2 : 0|16@1+ (0.01,0) [0|655.35] "s" Vector__XXX
 SG_ y_2 : 16|16@1+ (0.01,0) [0|135.0] "%VRef" Vector__XXX
 SG_ x_3 : 32|16@1+ (0.01,0) [0|655.35] "s" Vector__XXX
 SG_ y_3 : 48|16@1+ (0.01,0) [0|135.0] "%VRef" Vector__XXX

BO_ 2150217216 INV_HVRTMustTrip_Points_4_5_CMD: 8 HC
 SG_ x_4 : 0|16@1+ (0.01,0) [0|655.35] "s" Vector__XXX
 SG_ y_4 : 16|16@1+ (0.01,0) [0|135.0] "%VRef" Vector__XXX
 SG_ x_5 : 32|16@1+ (0.01,0) [0|655.35] "s" Vector__XXX
 SG_ y_5 : 48|16@1+ (0.01,0) [0|135.0] "%VRef" Vector__XXX

BO_ 2150217472 INV_HVRTMustTrip_Points_6_7_CMD: 8 HC
 SG_ x_6 : 0|16@1+ (0.01,0) [0|655.35] "s" Vector__XXX
 SG_ y_6 : 16|16@1+ (0.01,0) [0|135.0] "%VRef" Vector__XXX
 SG_ x_7 : 32|16@1+ (0.01,0) [0|655.35] "s" Vector__XXX
 SG_ y_7 : 48|16@1+ (0.01,0) [0|135.0] "%VRef" Vector__XXX

BO_ 2150217728 INV_HVRTMustTrip_Points_8_9_CMD: 8 HC
 SG_ x_8 : 0|16@1+ (0.01,0) [0|655.35] "s" Vector__XXX
 SG_ y_8 : 16|16@1+ (0.01,0) [0|135.0] "%VRef" Vector__XXX
 SG_ x_9 : 32|16@1+ (0.01,0) [0|655.35] "s" Vector__XXX
 SG_ y_9 : 48|16@1+ (0.01,0) [0|135.0] "%VRef" Vector__XXX

BO_ 2149167104 INV_HVRTMustTrip_CurveStatus_RSP: 2 INV
 SG_ CurveEnabled : 0|8@1+ (1,0) [0|255] "" Vector__XXX
 SG_ CurveUpdateStatus : 8|8@1+ (1,0) [0|255] "" Vector__XXX

BO_ 2149167360 INV_HVRTMustTrip_Metadata_RSP: 1 INV
 SG_ CurveNumPoints : 0|8@1+ (1,0) [0|10] "" Vector__XXX

BO_ 2149167616 INV_HVRTMustTrip_Timings_RSP: 8 INV
 SG_ OpenLoopTms : 0|16@1+ (0.01,0) [0|655.35] "%capability/s" Vector__XXX
 SG_ RampDecTms : 16|16@1+ (0.01,0) [0|655.35] "%capability/s" Vector__XXX
 SG_ RampIncTms : 32|16@1+ (0.01,0) [0|655.35] "%capability/s" Vector__XXX
 SG_ RampPT1 : 48|16@1+ (0.01,0) [0|655.35] "s" Vector__XXX

BO_ 2149168128 INV_HVRTMustTrip_Points_0_1_RSP: 8 INV
 SG_ x_0 : 0|16@1+ (0.01,0) [0|655.35] "s" Vector__XXX
 SG_ y_0 : 16|16@1+ (0.01,0) [0|135.0] "%VRef" Vector__XXX
 SG_ x_1 : 32|16@1+ (0.01,0) [0|655.35] "s" Vector__XXX
 SG_ y_1 : 48|16@1+ (0.01,0) [0|135.0] "%VRef" Vector__XXX

BO_ 2149168384 INV_HVRTMustTrip_Points_2_3_RSP: 8 INV
 SG_ x_2 : 0|16@1+ (0.01,0) [0|655.35] "s" Vector__XXX
 SG_ y_2 : 16|16@1+ (0.01,0) [0|135.0] "%VRef" Vector__XXX
 SG_ x_3 : 32|16@1+ (0.01,0) [0|655.35] "s" Vector__XXX
 SG_ y_3 : 48|16@1+ (0.01,0) [0|135.0] "%VRef" Vector__XXX

BO_ 2149168640 INV_HVRTMustTrip_Points_4_5_RSP: 8 INV
 SG_ x_4 : 0|16@1+ (0.01,0) [0|655.35] "s" Vector__XXX
 SG_ y_4 : 16|16@1+ (0.01,0) [0|135.0] "%VRef" Vector__XXX
 SG_ x_5 : 32|16@1+ (0.01,0) [0|655.35] "s" Vector__XXX
 SG_ y_5 : 48|16@1+ (0.01,0) [0|135.0] "%VRef" Vector__XXX

BO_ 2149168896 INV_HVRTMustTrip_Points_6_7_RSP: 8 INV
 SG_ x_6 : 0|16@1+ (0.01,0) [0|655.35] "s" Vector__XXX
 SG_ y_6 : 16|16@1+ (0.01,0) [0|135.0] "%VRef" Vector__XXX
 SG_ x_7 : 32|16@1+ (0.01,0) [0|655.35] "s" Vector__XXX
 SG_ y_7 : 48|16@1+ (0.01,0) [0|135.0] "%VRef" Vector__XXX

BO_ 2149169152 INV_HVRTMustTrip_Points_8_9_RSP: 8 INV
 SG_ x_8 : 0|16@1+ (0.01,0) [0|655.35] "s" Vector__XXX
 SG_ y_8 : 16|16@1+ (0.01,0) [0|135.0] "%VRef" Vector__XXX
 SG_ x_9 : 32|16@1+ (0.01,0) [0|655.35] "s" Vector__XXX
 SG_ y_9 : 48|16@1+ (0.01,0) [0|135.0] "%VRef" Vector__XXX

BO_ 2150219776 INV_LVRTMayTrip_CurveStatus_CMD: 2 HC
 SG_ CurveEnabled : 0|8@1+ (1,0) [0|255] "" Vector__XXX
 SG_ CurveUpdateStatus : 8|8@1+ (1,0) [0|255] "" Vector__XXX

BO_ 2150220032 INV_LVRTMayTrip_Metadata_CMD: 1 HC
 SG_ CurveNumPoints : 0|8@1+ (1,0) [0|10] "" Vector__XXX

BO_ 2150220288 INV_LVRTMayTrip_Timings_CMD: 8 HC
 SG_ OpenLoopTms : 0|16@1+ (0.01,0) [0|655.35] "%capability/s" Vector__XXX
 SG_ RampDecTms : 16|16@1+ (0.01,0) [0|655.35] "%capability/s" Vector__XXX
 SG_ RampIncTms : 32|16@1+ (0.01,0) [0|655.35] "%capability/s" Vector__XXX
 SG_ RampPT1 : 48|16@1+ (0.01,0) [0|655.35] "s" Vector__XXX

BO_ 2150220800 INV_LVRTMayTrip_Points_0_1_CMD: 8 HC
 SG_ x_0 : 0|16@1+ (0.01,0) [0|655.35] "s" Vector__XXX
 SG_ y_0 : 16|16@1+ (0.01,0) [0|135.0] "%VRef" Vector__XXX
 SG_ x_1 : 32|16@1+ (0.01,0) [0|655.35] "s" Vector__XXX
 SG_ y_1 : 48|16@1+ (0.01,0) [0|135.0] "%VRef" Vector__XXX

BO_ 2150221056 INV_LVRTMayTrip_Points_2_3_CMD: 8 HC
 SG_ x_2 : 0|16@1+ (0.01,0) [0|655.35] "s" Vector__XXX
 SG_ y_2 : 16|16@1+ (0.01,0) [0|135.0] "%VRef" Vector__XXX
 SG_ x_3 : 32|16@1+ (0.01,0) [0|655.35] "s" Vector__XXX
 SG_ y_3 : 48|16@1+ (0.01,0) [0|135.0] "%VRef" Vector__XXX

BO_ 2150221312 INV_LVRTMayTrip_Points_4_5_CMD: 8 HC
 SG_ x_4 : 0|16@1+ (0.01,0) [0|655.35] "s" Vector__XXX
 SG_ y_4 : 16|16@1+ (0.01,0) [0|135.0] "%VRef" Vector__XXX
 SG_ x_5 : 32|16@1+ (0.01,0) [0|655.35] "s" Vector__XXX
 SG_ y_5 : 48|16@1+ (0.01,0) [0|135.0] "%VRef" Vector__XXX

BO_ 2150221568 INV_LVRTMayTrip_Points_6_7_CMD: 8 HC
 SG_ x_6 : 0|16@1+ (0.01,0) [0|655.35] "s" Vector__XXX
 SG_ y_6 : 16|16@1+ (0.01,0) [0|135.0] "%VRef" Vector__XXX
 SG_ x_7 : 32|16@1+ (0.01,0) [0|655.35] "s" Vector__XXX
 SG_ y_7 : 48|16@1+ (0.01,0) [0|135.0] "%VRef" Vector__XXX

BO_ 2150221824 INV_LVRTMayTrip_Points_8_9_CMD: 8 HC
 SG_ x_8 : 0|16@1+ (0.01,0) [0|655.35] "s" Vector__XXX
 SG_ y_8 : 16|16@1+ (0.01,0) [0|135.0] "%VRef" Vector__XXX
 SG_ x_9 : 32|16@1+ (0.01,0) [0|655.35] "s" Vector__XXX
 SG_ y_9 : 48|16@1+ (0.01,0) [0|135.0] "%VRef" Vector__XXX

BO_ 2149171200 INV_LVRTMayTrip_CurveStatus_RSP: 2 INV
 SG_ CurveEnabled : 0|8@1+ (1,0) [0|255] "" Vector__XXX
 SG_ CurveUpdateStatus : 8|8@1+ (1,0) [0|255] "" Vector__XXX

BO_ 2149171456 INV_LVRTMayTrip_Metadata_RSP: 1 INV
 SG_ CurveNumPoints : 0|8@1+ (1,0) [0|10] "" Vector__XXX

BO_ 2149171712 INV_LVRTMayTrip_Timings_RSP: 8 INV
 SG_ OpenLoopTms : 0|16@1+ (0.01,0) [0|655.35] "%capability/s" Vector__XXX
 SG_ RampDecTms : 16|16@1+ (0.01,0) [0|655.35] "%capability/s" Vector__XXX
 SG_ RampIncTms : 32|16@1+ (0.01,0) [0|655.35] "%capability/s" Vector__XXX
 SG_ RampPT1 : 48|16@1+ (0.01,0) [0|655.35] "s" Vector__XXX

BO_ 2149172224 INV_LVRTMayTrip_Points_0_1_RSP: 8 INV
 SG_ x_0 : 0|16@1+ (0.01,0) [0|655.35] "s" Vector__XXX
 SG_ y_0 : 16|16@1+ (0.01,0) [0|135.0] "%VRef" Vector__XXX
 SG_ x_1 : 32|16@1+ (0.01,0) [0|655.35] "s" Vector__XXX
 SG_ y_1 : 48|16@1+ (0.01,0) [0|135.0] "%VRef" Vector__XXX

BO_ 2149172480 INV_LVRTMayTrip_Points_2_3_RSP: 8 INV
 SG_ x_2 : 0|16@1+ (0.01,0) [0|655.35] "s" Vector__XXX
 SG_ y_2 : 16|16@1+ (0.01,0) [0|135.0] "%VRef" Vector__XXX
 SG_ x_3 : 32|16@1+ (0.01,0) [0|655.35] "s" Vector__XXX
 SG_ y_3 : 48|16@1+ (0.01,0) [0|135.0] "%VRef" Vector__XXX

BO_ 2149172736 INV_LVRTMayTrip_Points_4_5_RSP: 8 INV
 SG_ x_4 : 0|16@1+ (0.01,0) [0|655.35] "s" Vector__XXX
 SG_ y_4 : 16|16@1+ (0.01,0) [0|135.0] "%VRef" Vector__XXX
 SG_ x_5 : 32|16@1+ (0.01,0) [0|655.35] "s" Vector__XXX
 SG_ y_5 : 48|16@1+ (0.01,0) [0|135.0] "%VRef" Vector__XXX

BO_ 2149172992 INV_LVRTMayTrip_Points_6_7_RSP: 8 INV
 SG_ x_6 : 0|16@1+ (0.01,0) [0|655.35] "s" Vector__XXX
 SG_ y_6 : 16|16@1+ (0.01,0) [0|135.0] "%VRef" Vector__XXX
 SG_ x_7 : 32|16@1+ (0.01,0) [0|655.35] "s" Vector__XXX
 SG_ y_7 : 48|16@1+ (0.01,0) [0|135.0] "%VRef" Vector__XXX

BO_ 2149173248 INV_LVRTMayTrip_Points_8_9_RSP: 8 INV
 SG_ x_8 : 0|16@1+ (0.01,0) [0|655.35] "s" Vector__XXX
 SG_ y_8 : 16|16@1+ (0.01,0) [0|135.0] "%VRef" Vector__XXX
 SG_ x_9 : 32|16@1+ (0.01,0) [0|655.35] "s" Vector__XXX
 SG_ y_9 : 48|16@1+ (0.01,0) [0|135.0] "%VRef" Vector__XXX

BO_ 2150223872 INV_LVRTMC_CurveStatus_CMD: 2 HC
 SG_ CurveEnabled : 0|8@1+ (1,0) [0|255] "" Vector__XXX
 SG_ CurveUpdateStatus : 8|8@1+ (1,0) [0|255] "" Vector__XXX

BO_ 2150224128 INV_LVRTMC_Metadata_CMD: 1 HC
 SG_ CurveNumPoints : 0|8@1+ (1,0) [0|10] "" Vector__XXX

BO_ 2150224384 INV_LVRTMC_Timings_CMD: 8 HC
 SG_ OpenLoopTms : 0|16@1+ (0.01,0) [0|655.35] "%capability/s" Vector__XXX
 SG_ RampDecTms : 16|16@1+ (0.01,0) [0|655.35] "%capability/s" Vector__XXX
 SG_ RampIncTms : 32|16@1+ (0.01,0) [0|655.35] "%capability/s" Vector__XXX
 SG_ RampPT1 : 48|16@1+ (0.01,0) [0|655.35] "s" Vector__XXX

BO_ 2150224896 INV_LVRTMC_Points_0_1_CMD: 8 HC
 SG_ x_0 : 0|16@1+ (0.01,0) [0|655.35] "s" Vector__XXX
 SG_ y_0 : 16|16@1+ (0.01,0) [0|135.0] "%VRef" Vector__XXX
 SG_ x_1 : 32|16@1+ (0.01,0) [0|655.35] "s" Vector__XXX
 SG_ y_1 : 48|16@1+ (0.01,0) [0|135.0] "%VRef" Vector__XXX

BO_ 2150225152 INV_LVRTMC_Points_2_3_CMD: 8 HC
 SG_ x_2 : 0|16@1+ (0.01,0) [0|655.35] "s" Vector__XXX
 SG_ y_2 : 16|16@1+ (0.01,0) [0|135.0] "%VRef" Vector__XXX
 SG_ x_3 : 32|16@1+ (0.01,0) [0|655.35] "s" Vector__XXX
 SG_ y_3 : 48|16@1+ (0.01,0) [0|135.0] "%VRef" Vector__XXX

BO_ 2150225408 INV_LVRTMC_Points_4_5_CMD: 8 HC
 SG_ x_4 : 0|16@1+ (0.01,0) [0|655.35] "s" Vector__XXX
 SG_ y_4 : 16|16@1+ (0.01,0) [0|135.0] "%VRef" Vector__XXX
 SG_ x_5 : 32|16@1+ (0.01,0) [0|655.35] "s" Vector__XXX
 SG_ y_5 : 48|16@1+ (0.01,0) [0|135.0] "%VRef" Vector__XXX

BO_ 2150225664 INV_LVRTMC_Points_6_7_CMD: 8 HC
 SG_ x_6 : 0|16@1+ (0.01,0) [0|655.35] "s" Vector__XXX
 SG_ y_6 : 16|16@1+ (0.01,0) [0|135.0] "%VRef" Vector__XXX
 SG_ x_7 : 32|16@1+ (0.01,0) [0|655.35] "s" Vector__XXX
 SG_ y_7 : 48|16@1+ (0.01,0) [0|135.0] "%VRef" Vector__XXX

BO_ 2150225920 INV_LVRTMC_Points_8_9_CMD: 8 HC
 SG_ x_8 : 0|16@1+ (0.01,0) [0|655.35] "s" Vector__XXX
 SG_ y_8 : 16|16@1+ (0.01,0) [0|135.0] "%VRef" Vector__XXX
 SG_ x_9 : 32|16@1+ (0.01,0) [0|655.35] "s" Vector__XXX
 SG_ y_9 : 48|16@1+ (0.01,0) [0|135.0] "%VRef" Vector__XXX

BO_ 2149175296 INV_LVRTMC_CurveStatus_RSP: 2 INV
 SG_ CurveEnabled : 0|8@1+ (1,0) [0|255] "" Vector__XXX
 SG_ CurveUpdateStatus : 8|8@1+ (1,0) [0|255] "" Vector__XXX

BO_ 2149175552 INV_LVRTMC_Metadata_RSP: 1 INV
 SG_ CurveNumPoints : 0|8@1+ (1,0) [0|10] "" Vector__XXX

BO_ 2149175808 INV_LVRTMC_Timings_RSP: 8 INV
 SG_ OpenLoopTms : 0|16@1+ (0.01,0) [0|655.35] "%capability/s" Vector__XXX
 SG_ RampDecTms : 16|16@1+ (0.01,0) [0|655.35] "%capability/s" Vector__XXX
 SG_ RampIncTms : 32|16@1+ (0.01,0) [0|655.35] "%capability/s" Vector__XXX
 SG_ RampPT1 : 48|16@1+ (0.01,0) [0|655.35] "s" Vector__XXX

BO_ 2149176320 INV_LVRTMC_Points_0_1_RSP: 8 INV
 SG_ x_0 : 0|16@1+ (0.01,0) [0|655.35] "s" Vector__XXX
 SG_ y_0 : 16|16@1+ (0.01,0) [0|135.0] "%VRef" Vector__XXX
 SG_ x_1 : 32|16@1+ (0.01,0) [0|655.35] "s" Vector__XXX
 SG_ y_1 : 48|16@1+ (0.01,0) [0|135.0] "%VRef" Vector__XXX

BO_ 2149176576 INV_LVRTMC_Points_2_3_RSP: 8 INV
 SG_ x_2 : 0|16@1+ (0.01,0) [0|655.35] "s" Vector__XXX
 SG_ y_2 : 16|16@1+ (0.01,0) [0|135.0] "%VRef" Vector__XXX
 SG_ x_3 : 32|16@1+ (0.01,0) [0|655.35] "s" Vector__XXX
 SG_ y_3 : 48|16@1+ (0.01,0) [0|135.0] "%VRef" Vector__XXX

BO_ 2149176832 INV_LVRTMC_Points_4_5_RSP: 8 INV
 SG_ x_4 : 0|16@1+ (0.01,0) [0|655.35] "s" Vector__XXX
 SG_ y_4 : 16|16@1+ (0.01,0) [0|135.0] "%VRef" Vector__XXX
 SG_ x_5 : 32|16@1+ (0.01,0) [0|655.35] "s" Vector__XXX
 SG_ y_5 : 48|16@1+ (0.01,0) [0|135.0] "%VRef" Vector__XXX

BO_ 2149177088 INV_LVRTMC_Points_6_7_RSP: 8 INV
 SG_ x_6 : 0|16@1+ (0.01,0) [0|655.35] "s" Vector__XXX
 SG_ y_6 : 16|16@1+ (0.01,0) [0|135.0] "%VRef" Vector__XXX
 SG_ x_7 : 32|16@1+ (0.01,0) [0|655.35] "s" Vector__XXX
 SG_ y_7 : 48|16@1+ (0.01,0) [0|135.0] "%VRef" Vector__XXX

BO_ 2149177344 INV_LVRTMC_Points_8_9_RSP: 8 INV
 SG_ x_8 : 0|16@1+ (0.01,0) [0|655.35] "s" Vector__XXX
 SG_ y_8 : 16|16@1+ (0.01,0) [0|135.0] "%VRef" Vector__XXX
 SG_ x_9 : 32|16@1+ (0.01,0) [0|655.35] "s" Vector__XXX
 SG_ y_9 : 48|16@1+ (0.01,0) [0|135.0] "%VRef" Vector__XXX

BO_ 2150227968 INV_LVRTMustTrip_CurveStatus_CMD: 2 HC
 SG_ CurveEnabled : 0|8@1+ (1,0) [0|255] "" Vector__XXX
 SG_ CurveUpdateStatus : 8|8@1+ (1,0) [0|255] "" Vector__XXX

BO_ 2150228224 INV_LVRTMustTrip_Metadata_CMD: 1 HC
 SG_ CurveNumPoints : 0|8@1+ (1,0) [0|10] "" Vector__XXX

BO_ 2150228480 INV_LVRTMustTrip_Timings_CMD: 8 HC
 SG_ OpenLoopTms : 0|16@1+ (0.01,0) [0|655.35] "%capability/s" Vector__XXX
 SG_ RampDecTms : 16|16@1+ (0.01,0) [0|655.35] "%capability/s" Vector__XXX
 SG_ RampIncTms : 32|16@1+ (0.01,0) [0|655.35] "%capability/s" Vector__XXX
 SG_ RampPT1 : 48|16@1+ (0.01,0) [0|655.35] "s" Vector__XXX

BO_ 2150228992 INV_LVRTMustTrip_Points_0_1_CMD: 8 HC
 SG_ x_0 : 0|16@1+ (0.01,0) [0|655.35] "s" Vector__XXX
 SG_ y_0 : 16|16@1+ (0.01,0) [0|135.0] "%VRef" Vector__XXX
 SG_ x_1 : 32|16@1+ (0.01,0) [0|655.35] "s" Vector__XXX
 SG_ y_1 : 48|16@1+ (0.01,0) [0|135.0] "%VRef" Vector__XXX

BO_ 2150229248 INV_LVRTMustTrip_Points_2_3_CMD: 8 HC
 SG_ x_2 : 0|16@1+ (0.01,0) [0|655.35] "s" Vector__XXX
 SG_ y_2 : 16|16@1+ (0.01,0) [0|135.0] "%VRef" Vector__XXX
 SG_ x_3 : 32|16@1+ (0.01,0) [0|655.35] "s" Vector__XXX
 SG_ y_3 : 48|16@1+ (0.01,0) [0|135.0] "%VRef" Vector__XXX

BO_ 2150229504 INV_LVRTMustTrip_Points_4_5_CMD: 8 HC
 SG_ x_4 : 0|16@1+ (0.01,0) [0|655.35] "s" Vector__XXX
 SG_ y_4 : 16|16@1+ (0.01,0) [0|135.0] "%VRef" Vector__XXX
 SG_ x_5 : 32|16@1+ (0.01,0) [0|655.35] "s" Vector__XXX
 SG_ y_5 : 48|16@1+ (0.01,0) [0|135.0] "%VRef" Vector__XXX

BO_ 2150229760 INV_LVRTMustTrip_Points_6_7_CMD: 8 HC
 SG_ x_6 : 0|16@1+ (0.01,0) [0|655.35] "s" Vector__XXX
 SG_ y_6 : 16|16@1+ (0.01,0) [0|135.0] "%VRef" Vector__XXX
 SG_ x_7 : 32|16@1+ (0.01,0) [0|655.35] "s" Vector__XXX
 SG_ y_7 : 48|16@1+ (0.01,0) [0|135.0] "%VRef" Vector__XXX

BO_ 2150230016 INV_LVRTMustTrip_Points_8_9_CMD: 8 HC
 SG_ x_8 : 0|16@1+ (0.01,0) [0|655.35] "s" Vector__XXX
 SG_ y_8 : 16|16@1+ (0.01,0) [0|135.0] "%VRef" Vector__XXX
 SG_ x_9 : 32|16@1+ (0.01,0) [0|655.35] "s" Vector__XXX
 SG_ y_9 : 48|16@1+ (0.01,0) [0|135.0] "%VRef" Vector__XXX

BO_ 2149179392 INV_LVRTMustTrip_CurveStatus_RSP: 2 INV
 SG_ CurveEnabled : 0|8@1+ (1,0) [0|255] "" Vector__XXX
 SG_ CurveUpdateStatus : 8|8@1+ (1,0) [0|255] "" Vector__XXX

BO_ 2149179648 INV_LVRTMustTrip_Metadata_RSP: 1 INV
 SG_ CurveNumPoints : 0|8@1+ (1,0) [0|10] "" Vector__XXX

BO_ 2149179904 INV_LVRTMustTrip_Timings_RSP: 8 INV
 SG_ OpenLoopTms : 0|16@1+ (0.01,0) [0|655.35] "%capability/s" Vector__XXX
 SG_ RampDecTms : 16|16@1+ (0.01,0) [0|655.35] "%capability/s" Vector__XXX
 SG_ RampIncTms : 32|16@1+ (0.01,0) [0|655.35] "%capability/s" Vector__XXX
 SG_ RampPT1 : 48|16@1+ (0.01,0) [0|655.35] "s" Vector__XXX

BO_ 2149180416 INV_LVRTMustTrip_Points_0_1_RSP: 8 INV
 SG_ x_0 : 0|16@1+ (0.01,0) [0|655.35] "s" Vector__XXX
 SG_ y_0 : 16|16@1+ (0.01,0) [0|135.0] "%VRef" Vector__XXX
 SG_ x_1 : 32|16@1+ (0.01,0) [0|655.35] "s" Vector__XXX
 SG_ y_1 : 48|16@1+ (0.01,0) [0|135.0] "%VRef" Vector__XXX

BO_ 2149180672 INV_LVRTMustTrip_Points_2_3_RSP: 8 INV
 SG_ x_2 : 0|16@1+ (0.01,0) [0|655.35] "s" Vector__XXX
 SG_ y_2 : 16|16@1+ (0.01,0) [0|135.0] "%VRef" Vector__XXX
 SG_ x_3 : 32|16@1+ (0.01,0) [0|655.35] "s" Vector__XXX
 SG_ y_3 : 48|16@1+ (0.01,0) [0|135.0] "%VRef" Vector__XXX

BO_ 2149180928 INV_LVRTMustTrip_Points_4_5_RSP: 8 INV
 SG_ x_4 : 0|16@1+ (0.01,0) [0|655.35] "s" Vector__XXX
 SG_ y_4 : 16|16@1+ (0.01,0) [0|135.0] "%VRef" Vector__XXX
 SG_ x_5 : 32|16@1+ (0.01,0) [0|655.35] "s" Vector__XXX
 SG_ y_5 : 48|16@1+ (0.01,0) [0|135.0] "%VRef" Vector__XXX

BO_ 2149181184 INV_LVRTMustTrip_Points_6_7_RSP: 8 INV
 SG_ x_6 : 0|16@1+ (0.01,0) [0|655.35] "s" Vector__XXX
 SG_ y_6 : 16|16@1+ (0.01,0) [0|135.0] "%VRef" Vector__XXX
 SG_ x_7 : 32|16@1+ (0.01,0) [0|655.35] "s" Vector__XXX
 SG_ y_7 : 48|16@1+ (0.01,0) [0|135.0] "%VRef" Vector__XXX

BO_ 2149181440 INV_LVRTMustTrip_Points_8_9_RSP: 8 INV
 SG_ x_8 : 0|16@1+ (0.01,0) [0|655.35] "s" Vector__XXX
 SG_ y_8 : 16|16@1+ (0.01,0) [0|135.0] "%VRef" Vector__XXX
 SG_ x_9 : 32|16@1+ (0.01,0) [0|655.35] "s" Vector__XXX
 SG_ y_9 : 48|16@1+ (0.01,0) [0|135.0] "%VRef" Vector__XXX

BO_ 2150232064 INV_WattVar_CurveStatus_CMD: 2 HC
 SG_ CurveEnabled : 0|8@1+ (1,0) [0|255] "" Vector__XXX
 SG_ CurveUpdateStatus : 8|8@1+ (1,0) [0|255] "" Vector__XXX

BO_ 2150232320 INV_WattVar_Metadata_CMD: 2 HC
 SG_ CurveNumPoints : 0|8@1+ (1,0) [0|10] "" Vector__XXX
 SG_ yRefType : 8|8@1+ (1,0) [0|255] "" Vector__XXX

BO_ 2150232576 INV_WattVar_Timings_CMD: 8 HC
 SG_ OpenLoopTms : 0|16@1+ (0.01,0) [0|655.35] "%capability/s" Vector__XXX
 SG_ RampDecTms : 16|16@1+ (0.01,0) [0|655.35] "%capability/s" Vector__XXX
 SG_ RampIncTms : 32|16@1+ (0.01,0) [0|655.35] "%capability/s" Vector__XXX
 SG_ RampPT1 : 48|16@1+ (0.01,0) [0|655.35] "s" Vector__XXX

BO_ 2150233088 INV_WattVar_Points_0_1_CMD: 8 HC
 SG_ x_0 : 0|16@1+ (0.01,0) [0|100.0] "%W capability" Vector__XXX
 SG_ y_0 : 16|16@1- (0.01,0) [-100.0|100.0] "%var capability" Vector__XXX
 SG_ x_1 : 32|16@1+ (0.01,0) [0|100.0] "%W capability" Vector__XXX
 SG_ y_1 : 48|16@1- (0.01,0) [-100.0|100.0] "%var capability" Vector__XXX

BO_ 2150233344 INV_WattVar_Points_2_3_CMD: 8 HC
 SG_ x_2 : 0|16@1+ (0.01,0) [0|100.0] "%W capability" Vector__XXX
 SG_ y_2 : 16|16@1- (0.01,0) [-100.0|100.0] "%var capability" Vector__XXX
 SG_ x_3 : 32|16@1+ (0.01,0) [0|100.0] "%W capability" Vector__XXX
 SG_ y_3 : 48|16@1- (0.01,0) [-100.0|100.0] "%var capability" Vector__XXX

BO_ 2150233600 INV_WattVar_Points_4_5_CMD: 8 HC
 SG_ x_4 : 0|16@1+ (0.01,0) [0|100.0] "%W capability" Vector__XXX
 SG_ y_4 : 16|16@1- (0.01,0) [-100.0|100.0] "%var capability" Vector__XXX
 SG_ x_5 : 32|16@1+ (0.01,0) [0|100.0] "%W capability" Vector__XXX
 SG_ y_5 : 48|16@1- (0.01,0) [-100.0|100.0] "%var capability" Vector__XXX

BO_ 2150233856 INV_WattVar_Points_6_7_CMD: 8 HC
 SG_ x_6 : 0|16@1+ (0.01,0) [0|100.0] "%W capability" Vector__XXX
 SG_ y_6 : 16|16@1- (0.01,0) [-100.0|100.0] "%var capability" Vector__XXX
 SG_ x_7 : 32|16@1+ (0.01,0) [0|100.0] "%W capability" Vector__XXX
 SG_ y_7 : 48|16@1- (0.01,0) [-100.0|100.0] "%var capability" Vector__XXX

BO_ 2150234112 INV_WattVar_Points_8_9_CMD: 8 HC
 SG_ x_8 : 0|16@1+ (0.01,0) [0|100.0] "%W capability" Vector__XXX
 SG_ y_8 : 16|16@1- (0.01,0) [-100.0|100.0] "%var capability" Vector__XXX
 SG_ x_9 : 32|16@1+ (0.01,0) [0|100.0] "%W capability" Vector__XXX
 SG_ y_9 : 48|16@1- (0.01,0) [-100.0|100.0] "%var capability" Vector__XXX

BO_ 2149183488 INV_WattVar_CurveStatus_RSP: 2 INV
 SG_ CurveEnabled : 0|8@1+ (1,0) [0|255] "" Vector__XXX
 SG_ CurveUpdateStatus : 8|8@1+ (1,0) [0|255] "" Vector__XXX

BO_ 2149183744 INV_WattVar_Metadata_RSP: 2 INV
 SG_ CurveNumPoints : 0|8@1+ (1,0) [0|10] "" Vector__XXX
 SG_ yRefType : 8|8@1+ (1,0) [0|255] "" Vector__XXX

BO_ 2149184000 INV_WattVar_Timings_RSP: 8 INV
 SG_ OpenLoopTms : 0|16@1+ (0.01,0) [0|655.35] "%capability/s" Vector__XXX
 SG_ RampDecTms : 16|16@1+ (0.01,0) [0|655.35] "%capability/s" Vector__XXX
 SG_ RampIncTms : 32|16@1+ (0.01,0) [0|655.35] "%capability/s" Vector__XXX
 SG_ RampPT1 : 48|16@1+ (0.01,0) [0|655.35] "s" Vector__XXX

BO_ 2149184512 INV_WattVar_Points_0_1_RSP: 8 INV
 SG_ x_0 : 0|16@1+ (0.01,0) [0|100.0] "%W capability" Vector__XXX
 SG_ y_0 : 16|16@1- (0.01,0) [-100.0|100.0] "%var capability" Vector__XXX
 SG_ x_1 : 32|16@1+ (0.01,0) [0|100.0] "%W capability" Vector__XXX
 SG_ y_1 : 48|16@1- (0.01,0) [-100.0|100.0] "%var capability" Vector__XXX

BO_ 2149184768 INV_WattVar_Points_2_3_RSP: 8 INV
 SG_ x_2 : 0|16@1+ (0.01,0) [0|100.0] "%W capability" Vector__XXX
 SG_ y_2 : 16|16@1- (0.01,0) [-100.0|100.0] "%var capability" Vector__XXX
 SG_ x_3 : 32|16@1+ (0.01,0) [0|100.0] "%W capability" Vector__XXX
 SG_ y_3 : 48|16@1- (0.01,0) [-100.0|100.0] "%var capability" Vector__XXX

BO_ 2149185024 INV_WattVar_Points_4_5_RSP: 8 INV
 SG_ x_4 : 0|16@1+ (0.01,0) [0|100.0] "%W capability" Vector__XXX
 SG_ y_4 : 16|16@1- (0.01,0) [-100.0|100.0] "%var capability" Vector__XXX
 SG_ x_5 : 32|16@1+ (0.01,0) [0|100.0] "%W capability" Vector__XXX
 SG_ y_5 : 48|16@1- (0.01,0) [-100.0|100.0] "%var capability" Vector__XXX

BO_ 2149185280 INV_WattVar_Points_6_7_RSP: 8 INV
 SG_ x_6 : 0|16@1+ (0.01,0) [0|100.0] "%W capability" Vector__XXX
 SG_ y_6 : 16|16@1- (0.01,0) [-100.0|100.0] "%var capability" Vector__XXX
 SG_ x_7 : 32|16@1+ (0.01,0) [0|100.0] "%W capability" Vector__XXX
 SG_ y_7 : 48|16@1- (0.01,0) [-100.0|100.0] "%var capability" Vector__XXX

BO_ 2149185536 INV_WattVar_Points_8_9_RSP: 8 INV
 SG_ x_8 : 0|16@1+ (0.01,0) [0|100.0] "%W capability" Vector__XXX
 SG_ y_8 : 16|16@1- (0.01,0) [-100.0|100.0] "%var capability" Vector__XXX
 SG_ x_9 : 32|16@1+ (0.01,0) [0|100.0] "%W capability" Vector__XXX
 SG_ y_9 : 48|16@1- (0.01,0) [-100.0|100.0] "%var capability" Vector__XXX

BO_ 2150173696 INV_LimitMaxAPEnable_CMD: 1 HC
 SG_ enabled : 0|8@1+ (1,0) [0|255] "" Vector__XXX

BO_ 2150173952 INV_LimitMaxAP_CMD: 2 HC
 SG_ value : 0|16@1+ (0.01,0) [0|100] "%capability" Vector__XXX

BO_ 2150174208 INV_APEnable_CMD: 1 HC
 SG_ enabled : 0|8@1+ (1,0) [0|255] "" Vector__XXX

BO_ 2150174464 INV_AP_CMD: 2 HC
 SG_ value : 0|16@1- (0.01,0) [-100|100] "%capability" Vector__XXX

BO_ 2150174720 INV_EnterServiceThr_CMD: 8 HC
 SG_ ESHighVolt : 0|16@1+ (0.01,0) [0|655.35] "%nominal" Vector__XXX
 SG_ ESLowVolt : 16|16@1+ (0.01,0) [0|655.35] "%nominal" Vector__XXX
 SG_ ESHighFreq : 32|16@1+ (0.01,0) [0|655.35] "Hz" Vector__XXX
 SG_ ESLowFreq : 48|16@1+ (0.01,0) [0|655.35] "Hz" Vector__XXX

BO_ 2150174976 INV_EnterServiceDelay_CMD: 8 HC
 SG_ ESDelay : 0|32@1+ (0.01,0) [0|42949672.95] "s" Vector__XXX
 SG_ ESRandomDelay : 32|32@1+ (0.01,0) [0|42949672.95] "s" Vector__XXX

BO_ 2150175232 INV_EnterServiceRamp_CMD: 4 HC
 SG_ ESRampTms : 0|32@1+ (0.01,0) [0|42949672.95] "s" Vector__XXX

BO_ 2150175488 INV_FreqDroopEnable_CMD: 1 HC
 SG_ enabled : 0|8@1+ (1,0) [0|255] "" Vector__XXX

BO_ 2150175744 INV_FreqDroopDeadbands_CMD: 8 HC
 SG_ dbof : 0|32@1+ (0.001,0) [0|4294967.295] "Hz" Vector__XXX
 SG_ dbuf : 32|32@1+ (0.001,0) [0|4294967.295] "Hz" Vector__XXX

BO_ 2150176000 INV_FreqDroopChange_CMD: 6 HC
 SG_ kof : 0|16@1+ (0.001,0) [0|65.535] "" Vector__XXX
 SG_ kuf : 16|16@1+ (0.001,0) [0|65.535] "" Vector__XXX
 SG_ RspTms : 32|16@1+ (0.01,0) [0|655.35] "s" Vector__XXX

BO_ 2150176256 INV_PFInjectEnable_CMD: 1 HC
 SG_ enabled : 0|8@1+ (1,0) [0|255] "" Vector__XXX

BO_ 2150176512 INV_PFInjectParams_CMD: 3 HC
 SG_ displacement : 0|16@1+ (0.001,0) [0|65.535] "" Vector__XXX
 SG_ excitation : 16|8@1+ (1,0) [0|255] "" Vector__XXX

BO_ 2150176768 INV_PFAbsorbEnable_CMD: 1 HC
 SG_ enabled : 0|8@1+ (1,0) [0|255] "" Vector__XXX

BO_ 2150177024 INV_PFAbsorbParams_CMD: 3 HC
 SG_ displacement : 0|16@1+ (0.001,0) [0|65.535] "" Vector__XXX
 SG_ excitation : 16|8@1+ (1,0) [0|255] "" Vector__XXX

BO_ 2150177280 INV_ReactivePowerEnable_CMD: 1 HC
 SG_ enabled : 0|8@1+ (1,0) [0|255] "" Vector__XXX

BO_ 2150177536 INV_ReactivePower_CMD: 3 HC
 SG_ value : 0|16@1- (0.01,0) [-100|100] "%capability" Vector__XXX
 SG_ refType : 16|8@1+ (1,0) [0|255] "" Vector__XXX

BO_ 2150177792 INV_RampRate_CMD: 4 HC
 SG_ setGradW : 0|16@1+ (0.01,0) [0|655.35] "%setWMax/s" Vector__XXX
 SG_ setSoftGradW : 16|16@1+ (0.01,0) [0|655.35] "%setWMax/s" Vector__XXX

BO_ 2149125120 INV_LimitMaxAPEnable_RSP: 1 INV
 SG_ enabled : 0|8@1+ (1,0) [0|255] "" Vector__XXX

BO_ 2149125376 INV_LimitMaxAP_RSP: 2 INV
 SG_ value : 0|16@1+ (0.01,0) [0|100] "%capability" Vector__XXX

BO_ 2149125632 INV_APEnable_RSP: 1 INV
 SG_ enabled : 0|8@1+ (1,0) [0|255] "" Vector__XXX

BO_ 2149125888 INV_AP_RSP: 2 INV
 SG_ value : 0|16@1- (0.01,0) [-100|100] "%capability" Vector__XXX

BO_ 2149126144 INV_EnterServiceThr_RSP: 8 INV
 SG_ ESHighVolt : 0|16@1+ (0.01,0) [0|655.35] "%nominal" Vector__XXX
 SG_ ESLowVolt : 16|16@1+ (0.01,0) [0|655.35] "%nominal" Vector__XXX
 SG_ ESHighFreq : 32|16@1+ (0.01,0) [0|655.35] "Hz" Vector__XXX
 SG_ ESLowFreq : 48|16@1+ (0.01,0) [0|655.35] "Hz" Vector__XXX

BO_ 2149126400 INV_EnterServiceDelay_RSP: 8 INV
 SG_ ESDelay : 0|32@1+ (0.01,0) [0|42949672.95] "s" Vector__XXX
 SG_ ESRandomDelay : 32|32@1+ (0.01,0) [0|42949672.95] "s" Vector__XXX

BO_ 2149126656 INV_EnterServiceRamp_RSP: 4 INV
 SG_ ESRampTms : 0|32@1+ (0.01,0) [0|42949672.95] "s" Vector__XXX

BO_ 2149126912 INV_FreqDroopEnable_RSP: 1 INV
 SG_ enabled : 0|8@1+ (1,0) [0|255] "" Vector__XXX

BO_ 2149127168 INV_FreqDroopDeadbands_RSP: 8 INV
 SG_ dbof : 0|32@1+ (0.001,0) [0|4294967.295] "Hz" Vector__XXX
 SG_ dbuf : 32|32@1+ (0.001,0) [0|4294967.295] "Hz" Vector__XXX

BO_ 2149127424 INV_FreqDroopChange_RSP: 6 INV
 SG_ kof : 0|16@1+ (0.001,0) [0|65.535] "" Vector__XXX
 SG_ kuf : 16|16@1+ (0.001,0) [0|65.535] "" Vector__XXX
 SG_ RspTms : 32|16@1+ (0.01,0) [0|655.35] "s" Vector__XXX

BO_ 2149127680 INV_PFInjectEnable_RSP: 1 INV
 SG_ enabled : 0|8@1+ (1,0) [0|255] "" Vector__XXX

BO_ 2149127936 INV_PFInjectParams_RSP: 3 INV
 SG_ displacement : 0|16@1+ (0.001,0) [0|65.535] "" Vector__XXX
 SG_ excitation : 16|8@1+ (1,0) [0|255] "" Vector__XXX

BO_ 2149128192 INV_PFAbsorbEnable_RSP: 1 INV
 SG_ enabled : 0|8@1+ (1,0) [0|255] "" Vector__XXX

BO_ 2149128448 INV_PFAbsorbParams_RSP: 3 INV
 SG_ displacement : 0|16@1+ (0.001,0) [0|65.535] "" Vector__XXX
 SG_ excitation : 16|8@1+ (1,0) [0|255] "" Vector__XXX

BO_ 2149128704 INV_ReactivePowerEnable_RSP: 1 INV
 SG_ enabled : 0|8@1+ (1,0) [0|255] "" Vector__XXX

BO_ 2149128960 INV_ReactivePower_RSP: 3 INV
 SG_ value : 0|16@1- (0.01,0) [-100|100] "%capability" Vector__XXX
 SG_ refType : 16|8@1+ (1,0) [0|255] "" Vector__XXX

BO_ 2149129216 INV_RampRate_RSP: 4 INV
 SG_ setGradW : 0|16@1+ (0.01,0) [0|655.35] "%setWMax/s" Vector__XXX
 SG_ setSoftGradW : 16|16@1+ (0.01,0) [0|655.35] "%setWMax/s" Vector__XXX

CM_ BO_ 2148929536 "This message encodes the sensed telemetry for power values";
CM_ BO_ 2150174464 "This message encodes the active power setpoint (CMD) or its acknowledgement (RSP)";
CM_ BO_ 2150177536 "This message encodes the reactive power setpoint (CMD) or its acknowledgement (RSP)";
CM_ BO_ 2149125888 "This message encodes the active power setpoint (CMD) or its acknowledgement (RSP)";
CM_ BO_ 2149128960 "This message encodes the reactive power setpoint (CMD) or its acknowledgement (RSP)";
BA_DEF_  "BusType" STRING ;
BA_DEF_  "DBName" STRING ;
BA_DEF_  "Baudrate" INT 0 1000000;
BA_DEF_  "VFrameFormat" ENUM  "StandardCAN","ExtendedCAN","reserved","J1939PG","reserved","reserved","reserved","reserved","reserved","reserved","reserved","reserved","reserved","reserved","StandardCAN_FD","ExtendedCAN_FD";
BA_DEF_ SG_  "SystemSignalLongSymbol" STRING ;
BA_DEF_DEF_  "BusType" "CAN";
BA_DEF_DEF_  "DBName" "Lunar ESS";
BA_DEF_DEF_  "Baudrate" 500000;
BA_DEF_DEF_  "VFrameFormat" "0";
BA_DEF_DEF_  "SystemSignalLongSymbol" "";
BA_ "VFrameFormat" 1;
BA_ "SystemSignalLongSymbol" SG_ 2151683840 SatefyStatusA_OCDischargeProt_fa "SatefyStatusA_OCDischargeProt_fault";
BA_ "SystemSignalLongSymbol" SG_ 2151683840 SafetyStatusB_UTempDischarge_fau "SafetyStatusB_UTempDischarge_fault";
BA_ "SystemSignalLongSymbol" SG_ 2151683840 SafetyStatusB_OTempDischarge_fau "SafetyStatusB_OTempDischarge_fault";
BA_ "SystemSignalLongSymbol" SG_ 2151683840 SafetyStatusC_OCDischgLatch_faul "SafetyStatusC_OCDischgLatch_fault";
BA_ "SystemSignalLongSymbol" SG_ 2151683840 SafetyStatusC_SCDischgLatch_faul "SafetyStatusC_SCDischgLatch_fault";
BA_ "SystemSignalLongSymbol" SG_ 2151684096 SatefyAlertA_OCDischargeProt_ale "SatefyAlertA_OCDischargeProt_alert";
BA_ "SystemSignalLongSymbol" SG_ 2151684096 SafetyAlertB_UTempDischarge_aler "SafetyAlertB_UTempDischarge_alert";
BA_ "SystemSignalLongSymbol" SG_ 2151684096 SafetyAlertB_OTempDischarge_aler "SafetyAlertB_OTempDischarge_alert";
BA_ "SystemSignalLongSymbol" SG_ 2151682048 BB_F001_PrimaryCellUndervoltageA "BB_F001_PrimaryCellUndervoltageAlert_ADBMS";
BA_ "SystemSignalLongSymbol" SG_ 2151682048 BB_F002_SecondaryCellUndervoltag "BB_F002_SecondaryCellUndervoltagAlert_BQ";
BA_ "SystemSignalLongSymbol" SG_ 2151682048 BB_F005_CellMismatchMeasurementA "BB_F005_CellMismatchMeasurementAlert";
BA_ "SystemSignalLongSymbol" SG_ 2151682048 BB_F008_HW_CellUndervoltageAlert "BB_F008_HW_CellUndervoltageAlert_BQ";
BA_ "SystemSignalLongSymbol" SG_ 2151682048 BB_F009_HW_CellOverVoltageAlert_ "BB_F009_HW_CellOverVoltageAlert_BQ";
BA_ "SystemSignalLongSymbol" SG_ 2151682048 BB_F011_OvercurrentDischargeAler "BB_F011_OvercurrentDischargeAlert";
BA_ "SystemSignalLongSymbol" SG_ 2151682048 BB_F017_InternalVSSMEasurementFa "BB_F017_InternalVSSMEasurementFailAlert";
BA_ "SystemSignalLongSymbol" SG_ 2151682048 BB_F019_StackVsSumCellMismatchAl "BB_F019_StackVsSumCellMismatchAlert";
BA_ "SystemSignalLongSymbol" SG_ 2152728576 GIP_Load_TotalActiveEnergyImport "GIP_Load_TotalActiveEnergyImported";
BA_ "SystemSignalLongSymbol" SG_ 2152728576 GIP_Load_TotalActiveEnergyExport "GIP_Load_TotalActiveEnergyExported";
BA_ "SystemSignalLongSymbol" SG_ 2152728832 GIP_Grid_TotalActiveEnergyImport "GIP_Grid_TotalActiveEnergyImported";
BA_ "SystemSignalLongSymbol" SG_ 2152728832 GIP_Grid_TotalActiveEnergyExport "GIP_Grid_TotalActiveEnergyExported";
VAL_ 2150630656 BB_StateReq 0 "Unknown" 2 "Block_Down" 3 "Active" 6 "Low_Voltage" 7 "Hibernate" ;
VAL_ 2151678208 BatteryBlockState 0 "Unknown" 1 "Init" 2 "Block_Down" 3 "Active" 4 "Precharge" 5 "Fault" 6 "Low_Voltage" ;
VAL_ 2151678208 PrechargeState 0 "Unknown" 1 "BusOff" 2 "WaitingForBq" 3 "BuckMode" 4 "ChargingFlyingCaps" 5 "Complete" 6 "Fault" ;
VAL_ 2152726784 GIP_State 3 "Off-Grid" 2 "On-Grid" 1 "Initializing" 0 "Testing" ;
VAL_ 2152726784 GIP_Relay_State 5 "Closed_Cooldown" 4 "Closing" 3 "Open" 2 "Open_Cooldown" 1 "Opening" 0 "Closed" ;
VAL_ 2148991232 InvState 3 "Fault" 2 "Grid_Forming" 1 "No_Service" 0 "Unknown" ;
VAL_ 2150178816 CurveUpdateStatus 1 "InProgress" 0 "Completed" ;
VAL_ 2150179072 yRefType 0 "SetMaxW" 1 "SetMaxVar" 2 "StatVarAvail" ;
VAL_ 2149130240 CurveUpdateStatus 1 "InProgress" 0 "Completed" ;
VAL_ 2149130496 yRefType 0 "SetMaxW" 1 "SetMaxVar" 2 "StatVarAvail" ;
VAL_ 2150182912 CurveUpdateStatus 1 "InProgress" 0 "Completed" ;
VAL_ 2149134336 CurveUpdateStatus 1 "InProgress" 0 "Completed" ;
VAL_ 2150187008 CurveUpdateStatus 1 "InProgress" 0 "Completed" ;
VAL_ 2150187264 yRefType 0 "SetMaxW" 1 "StatWAvail" ;
VAL_ 2149138432 CurveUpdateStatus 1 "InProgress" 0 "Completed" ;
VAL_ 2149138688 yRefType 0 "SetMaxW" 1 "StatWAvail" ;
VAL_ 2150191104 CurveUpdateStatus 1 "InProgress" 0 "Completed" ;
VAL_ 2149142528 CurveUpdateStatus 1 "InProgress" 0 "Completed" ;
VAL_ 2150195200 CurveUpdateStatus 1 "InProgress" 0 "Completed" ;
VAL_ 2149146624 CurveUpdateStatus 1 "InProgress" 0 "Completed" ;
VAL_ 2150199296 CurveUpdateStatus 1 "InProgress" 0 "Completed" ;
VAL_ 2149150720 CurveUpdateStatus 1 "InProgress" 0 "Completed" ;
VAL_ 2150203392 CurveUpdateStatus 1 "InProgress" 0 "Completed" ;
VAL_ 2149154816 CurveUpdateStatus 1 "InProgress" 0 "Completed" ;
VAL_ 2150207488 CurveUpdateStatus 1 "InProgress" 0 "Completed" ;
VAL_ 2149158912 CurveUpdateStatus 1 "InProgress" 0 "Completed" ;
VAL_ 2150211584 CurveUpdateStatus 1 "InProgress" 0 "Completed" ;
VAL_ 2149163008 CurveUpdateStatus 1 "InProgress" 0 "Completed" ;
VAL_ 2150215680 CurveUpdateStatus 1 "InProgress" 0 "Completed" ;
VAL_ 2149167104 CurveUpdateStatus 1 "InProgress" 0 "Completed" ;
VAL_ 2150219776 CurveUpdateStatus 1 "InProgress" 0 "Completed" ;
VAL_ 2149171200 CurveUpdateStatus 1 "InProgress" 0 "Completed" ;
VAL_ 2150223872 CurveUpdateStatus 1 "InProgress" 0 "Completed" ;
VAL_ 2149175296 CurveUpdateStatus 1 "InProgress" 0 "Completed" ;
VAL_ 2150227968 CurveUpdateStatus 1 "InProgress" 0 "Completed" ;
VAL_ 2149179392 CurveUpdateStatus 1 "InProgress" 0 "Completed" ;
VAL_ 2150232064 CurveUpdateStatus 1 "InProgress" 0 "Completed" ;
VAL_ 2150232320 yRefType 0 "SetMaxW" 1 "SetMaxVar" 2 "StatVarAvail" ;
VAL_ 2149183488 CurveUpdateStatus 1 "InProgress" 0 "Completed" ;
VAL_ 2149183744 yRefType 0 "SetMaxW" 1 "SetMaxVar" 2 "StatVarAvail" ;
VAL_ 2150177536 refType 0 "SetMaxVar" 1 "StatVarAvail" ;
VAL_ 2149128960 refType 0 "SetMaxVar" 1 "StatVarAvail" ;
